VERSION ""

NS_ :

BS_:

BU_: XXX

BO_ 514 V_0x202: 8 XXX

BO_ 515 V_0x203: 8 XXX

BO_ 516 V_0x204: 8 XXX

BO_ 517 V_0x205: 8 XXX

BO_ 518 V_0x206: 8 XXX

BO_ 519 V_0x207: 8 XXX

BO_ 520 V_0x208: 8 XXX

BO_ 521 V_0x209: 8 XXX

BO_ 522 V_0x20a: 8 XXX

BO_ 523 V_0x20b: 8 XXX

BO_ 524 V_0x20c: 8 XXX

BO_ 568 V_0x238: 8 XXX

BO_ 569 V_0x239: 8 XXX

BO_ 570 V_0x23a: 8 XXX

BO_ 571 V_0x23b: 8 XXX

BO_ 572 V_0x23c: 8 XXX

BO_ 573 V_0x23d: 8 XXX

BO_ 574 V_0x23e: 8 XXX

BO_ 575 V_0x23f: 8 XXX

BO_ 576 V_0x240: 8 XXX

BO_ 577 V_0x241: 8 XXX

BO_ 578 V_0x242: 8 XXX

BO_ 579 V_0x243: 8 XXX

BO_ 580 V_0x244: 8 XXX

BO_ 581 V_0x245: 8 XXX

BO_ 582 V_0x246: 8 XXX

BO_ 583 V_0x247: 8 XXX

BO_ 584 V_0x248: 8 XXX

BO_ 585 V_0x249: 8 XXX

BO_ 586 V_0x24a: 8 XXX

BO_ 587 V_0x24b: 8 XXX

BO_ 588 V_0x24c: 8 XXX

BO_ 589 V_0x24d: 8 XXX

BO_ 590 V_0x24e: 8 XXX

BO_ 591 V_0x24f: 8 XXX

BO_ 592 V_0x250: 8 XXX

BO_ 593 V_0x251: 8 XXX

BO_ 594 V_0x252: 8 XXX

BO_ 595 V_0x253: 8 XXX

BO_ 596 V_0x254: 8 XXX

BO_ 597 V_0x255: 8 XXX

BO_ 602 V_0x25a: 8 XXX

BO_ 603 V_0x25b: 8 XXX

BO_ 604 V_0x25c: 8 XXX

BO_ 605 V_0x25d: 8 XXX

BO_ 606 V_0x25e: 8 XXX

BO_ 614 V_0x266: 8 XXX

BO_ 615 V_0x267: 8 XXX

BO_ 616 V_0x268: 8 XXX

BO_ 617 V_0x269: 8 XXX

BO_ 618 V_0x26a: 8 XXX

BO_ 619 V_0x26b: 8 XXX

BO_ 620 V_0x26c: 8 XXX

BO_ 621 V_0x26d: 8 XXX

BO_ 513 R_0x201: 8 XXX

BO_ 768 R_0x300: 8 XXX

BO_ 1024 R_0x400: 8 XXX

BO_ 1025 R_0x401: 8 XXX

BO_ 1026 R_0x402: 8 XXX

BO_ 1027 R_0x403: 8 XXX

BO_ 1028 R_0x404: 8 XXX

BO_ 1029 R_0x405: 8 XXX

BO_ 1030 R_0x406: 8 XXX

BO_ 1031 R_0x407: 8 XXX

BO_ 1032 R_0x408: 8 XXX

BO_ 1033 R_0x409: 8 XXX

BO_ 1034 R_0x40a: 8 XXX

BO_ 1035 R_0x40b: 8 XXX

BO_ 1036 R_0x40c: 8 XXX

BO_ 1037 R_0x40d: 8 XXX

BO_ 1038 R_0x40e: 8 XXX

BO_ 1039 R_0x40f: 8 XXX

BO_ 1040 R_0x410: 8 XXX

BO_ 1041 R_0x411: 8 XXX

BO_ 1042 R_0x412: 8 XXX

BO_ 1043 R_0x413: 8 XXX

BO_ 1044 R_0x414: 8 XXX

BO_ 1045 R_0x415: 8 XXX

BO_ 1046 R_0x416: 8 XXX

BO_ 1047 R_0x417: 8 XXX

BO_ 1048 R_0x418: 8 XXX

BO_ 1049 R_0x419: 8 XXX

BO_ 1050 R_0x41a: 8 XXX

BO_ 1051 R_0x41b: 8 XXX

BO_ 1052 R_0x41c: 8 XXX

BO_ 1053 R_0x41d: 8 XXX

BO_ 1054 R_0x41e: 8 XXX

BO_ 1055 R_0x41f: 8 XXX

BO_ 1056 R_0x420: 8 XXX

BO_ 1057 R_0x421: 8 XXX

BO_ 1058 R_0x422: 8 XXX

BO_ 1059 R_0x423: 8 XXX

BO_ 1060 R_0x424: 8 XXX

BO_ 1061 R_0x425: 8 XXX

BO_ 1062 R_0x426: 8 XXX

BO_ 1063 R_0x427: 8 XXX

BO_ 1248 R_0x4E0: 8 XXX
BO_ 1249 R_0x4E1: 8 XXX
BO_ 1250 R_0x4E2: 8 XXX
BO_ 1251 R_0x4E3: 8 XXX
BO_ 1252 R_0x4E4: 8 XXX
BO_ 1253 R_0x4E5: 8 XXX
BO_ 1254 R_0x4E6: 8 XXX
BO_ 1255 R_0x4E7: 8 XXX

BO_ 1530 R_0x5FA: 8 XXX
BO_ 1531 R_0x5FB: 8 XXX

BO_ 1533 R_0x5FD: 8 XXX
BO_ 1534 R_0x5FE: 8 XXX
BO_ 1535 R_0x5FF: 8 XXX

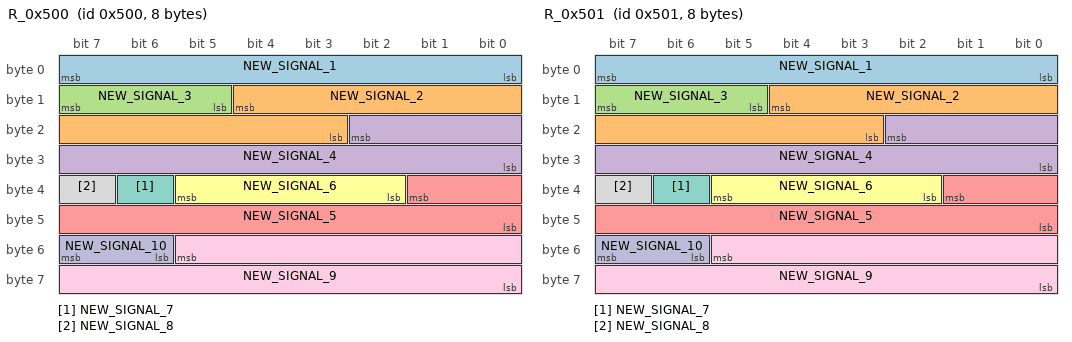
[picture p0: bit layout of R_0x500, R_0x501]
BO_ 1280 R_0x500: 8 XXX
 SG_ NEW_SIGNAL_1 : 7|8@0- (1,0) [-128|127] "" XXX
 SG_ NEW_SIGNAL_2 : 12|10@0- (0.2,0) [-102.4|102.2] "" XXX
 SG_ NEW_SIGNAL_3 : 15|3@0+ (1,0) [0|7] "" XXX
 SG_ NEW_SIGNAL_4 : 18|11@0+ (0.1,0) [0|204.7] "" XXX
 SG_ NEW_SIGNAL_5 : 33|10@0- (0.2,0) [-102.4|102.2] "" XXX
 SG_ NEW_SIGNAL_6 : 37|4@0+ (1,0) [0|255] "" XXX
 SG_ NEW_SIGNAL_7 : 38|1@0+ (1,0) [0|1] "" XXX
 SG_ NEW_SIGNAL_8 : 39|1@0+ (1,0) [0|1] "" XXX
 SG_ NEW_SIGNAL_9 : 53|14@0- (0.04,0) [-327.68|327.64] "" XXX
 SG_ NEW_SIGNAL_10 : 55|2@0+ (1,0) [0|3] "" XXX

BO_ 1281 R_0x501: 8 XXX
 SG_ NEW_SIGNAL_1 : 7|8@0- (1,0) [-128|127] "" XXX
 SG_ NEW_SIGNAL_2 : 12|10@0- (0.2,0) [-102.4|102.2] "" XXX
 SG_ NEW_SIGNAL_3 : 15|3@0+ (1,0) [0|7] "" XXX
 SG_ NEW_SIGNAL_4 : 18|11@0+ (0.1,0) [0|204.7] "" XXX
 SG_ NEW_SIGNAL_5 : 33|10@0- (0.2,0) [-102.4|102.2] "" XXX
 SG_ NEW_SIGNAL_6 : 37|4@0+ (1,0) [0|255] "" XXX
 SG_ NEW_SIGNAL_7 : 38|1@0+ (1,0) [0|1] "" XXX
 SG_ NEW_SIGNAL_8 : 39|1@0+ (1,0) [0|1] "" XXX
 SG_ NEW_SIGNAL_9 : 53|14@0- (0.04,0) [-327.68|327.64] "" XXX
 SG_ NEW_SIGNAL_10 : 55|2@0+ (1,0) [0|3] "" XXX

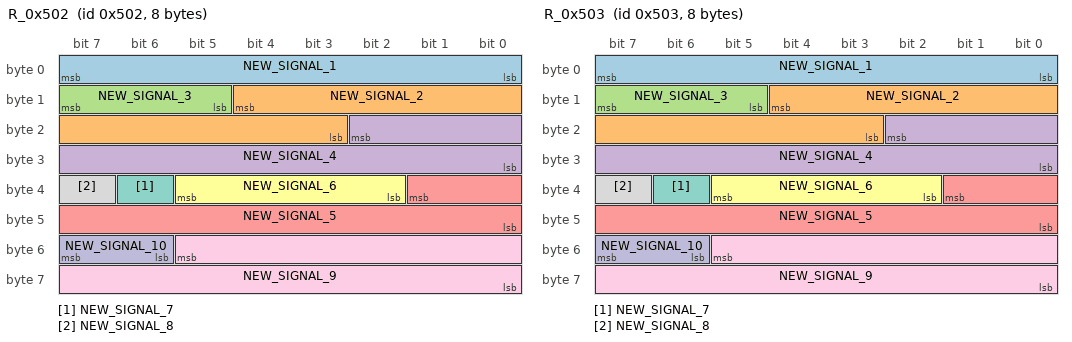
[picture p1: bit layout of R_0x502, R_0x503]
BO_ 1282 R_0x502: 8 XXX
 SG_ NEW_SIGNAL_1 : 7|8@0- (1,0) [-128|127] "" XXX
 SG_ NEW_SIGNAL_2 : 12|10@0- (0.2,0) [-102.4|102.2] "" XXX
 SG_ NEW_SIGNAL_3 : 15|3@0+ (1,0) [0|7] "" XXX
 SG_ NEW_SIGNAL_4 : 18|11@0+ (0.1,0) [0|204.7] "" XXX
 SG_ NEW_SIGNAL_5 : 33|10@0- (0.2,0) [-102.4|102.2] "" XXX
 SG_ NEW_SIGNAL_6 : 37|4@0+ (1,0) [0|255] "" XXX
 SG_ NEW_SIGNAL_7 : 38|1@0+ (1,0) [0|1] "" XXX
 SG_ NEW_SIGNAL_8 : 39|1@0+ (1,0) [0|1] "" XXX
 SG_ NEW_SIGNAL_9 : 53|14@0- (0.04,0) [-327.68|327.64] "" XXX
 SG_ NEW_SIGNAL_10 : 55|2@0+ (1,0) [0|3] "" XXX

BO_ 1283 R_0x503: 8 XXX
 SG_ NEW_SIGNAL_1 : 7|8@0- (1,0) [-128|127] "" XXX
 SG_ NEW_SIGNAL_2 : 12|10@0- (0.2,0) [-102.4|102.2] "" XXX
 SG_ NEW_SIGNAL_3 : 15|3@0+ (1,0) [0|7] "" XXX
 SG_ NEW_SIGNAL_4 : 18|11@0+ (0.1,0) [0|204.7] "" XXX
 SG_ NEW_SIGNAL_5 : 33|10@0- (0.2,0) [-102.4|102.2] "" XXX
 SG_ NEW_SIGNAL_6 : 37|4@0+ (1,0) [0|255] "" XXX
 SG_ NEW_SIGNAL_7 : 38|1@0+ (1,0) [0|1] "" XXX
 SG_ NEW_SIGNAL_8 : 39|1@0+ (1,0) [0|1] "" XXX
 SG_ NEW_SIGNAL_9 : 53|14@0- (0.04,0) [-327.68|327.64] "" XXX
 SG_ NEW_SIGNAL_10 : 55|2@0+ (1,0) [0|3] "" XXX

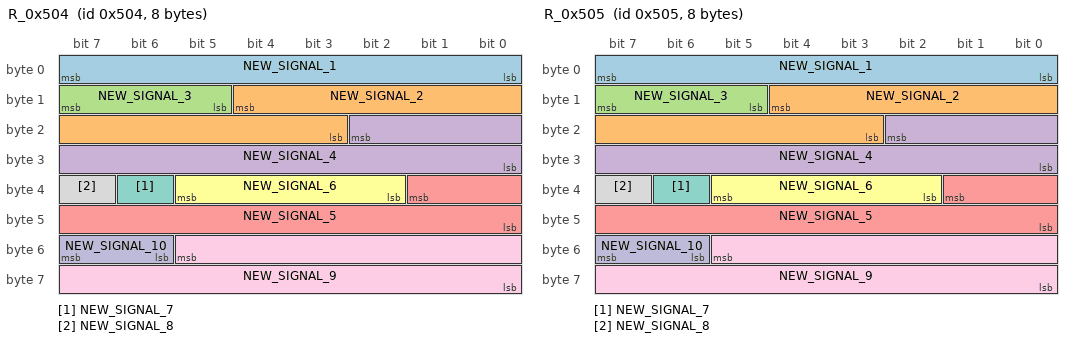
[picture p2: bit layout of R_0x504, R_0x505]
BO_ 1284 R_0x504: 8 XXX
 SG_ NEW_SIGNAL_1 : 7|8@0- (1,0) [-128|127] "" XXX
 SG_ NEW_SIGNAL_2 : 12|10@0- (0.2,0) [-102.4|102.2] "" XXX
 SG_ NEW_SIGNAL_3 : 15|3@0+ (1,0) [0|7] "" XXX
 SG_ NEW_SIGNAL_4 : 18|11@0+ (0.1,0) [0|204.7] "" XXX
 SG_ NEW_SIGNAL_5 : 33|10@0- (0.2,0) [-102.4|102.2] "" XXX
 SG_ NEW_SIGNAL_6 : 37|4@0+ (1,0) [0|255] "" XXX
 SG_ NEW_SIGNAL_7 : 38|1@0+ (1,0) [0|1] "" XXX
 SG_ NEW_SIGNAL_8 : 39|1@0+ (1,0) [0|1] "" XXX
 SG_ NEW_SIGNAL_9 : 53|14@0- (0.04,0) [-327.68|327.64] "" XXX
 SG_ NEW_SIGNAL_10 : 55|2@0+ (1,0) [0|3] "" XXX

BO_ 1285 R_0x505: 8 XXX
 SG_ NEW_SIGNAL_1 : 7|8@0- (1,0) [-128|127] "" XXX
 SG_ NEW_SIGNAL_2 : 12|10@0- (0.2,0) [-102.4|102.2] "" XXX
 SG_ NEW_SIGNAL_3 : 15|3@0+ (1,0) [0|7] "" XXX
 SG_ NEW_SIGNAL_4 : 18|11@0+ (0.1,0) [0|204.7] "" XXX
 SG_ NEW_SIGNAL_5 : 33|10@0- (0.2,0) [-102.4|102.2] "" XXX
 SG_ NEW_SIGNAL_6 : 37|4@0+ (1,0) [0|255] "" XXX
 SG_ NEW_SIGNAL_7 : 38|1@0+ (1,0) [0|1] "" XXX
 SG_ NEW_SIGNAL_8 : 39|1@0+ (1,0) [0|1] "" XXX
 SG_ NEW_SIGNAL_9 : 53|14@0- (0.04,0) [-327.68|327.64] "" XXX
 SG_ NEW_SIGNAL_10 : 55|2@0+ (1,0) [0|3] "" XXX

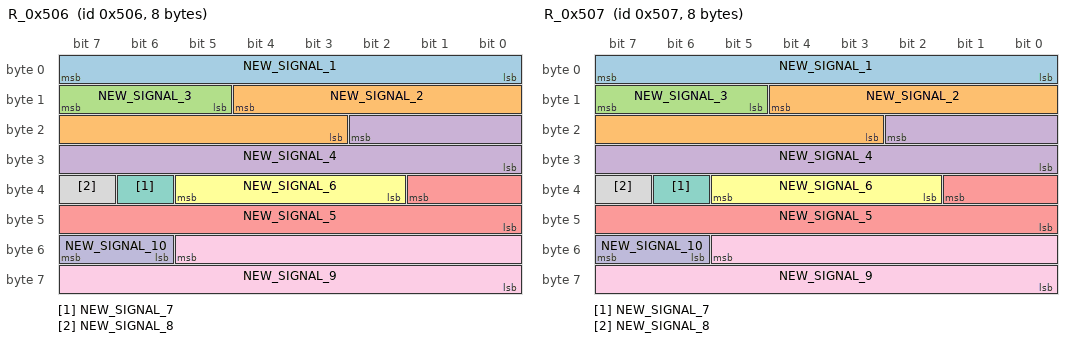
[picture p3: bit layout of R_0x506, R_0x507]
BO_ 1286 R_0x506: 8 XXX
 SG_ NEW_SIGNAL_1 : 7|8@0- (1,0) [-128|127] "" XXX
 SG_ NEW_SIGNAL_2 : 12|10@0- (0.2,0) [-102.4|102.2] "" XXX
 SG_ NEW_SIGNAL_3 : 15|3@0+ (1,0) [0|7] "" XXX
 SG_ NEW_SIGNAL_4 : 18|11@0+ (0.1,0) [0|204.7] "" XXX
 SG_ NEW_SIGNAL_5 : 33|10@0- (0.2,0) [-102.4|102.2] "" XXX
 SG_ NEW_SIGNAL_6 : 37|4@0+ (1,0) [0|255] "" XXX
 SG_ NEW_SIGNAL_7 : 38|1@0+ (1,0) [0|1] "" XXX
 SG_ NEW_SIGNAL_8 : 39|1@0+ (1,0) [0|1] "" XXX
 SG_ NEW_SIGNAL_9 : 53|14@0- (0.04,0) [-327.68|327.64] "" XXX
 SG_ NEW_SIGNAL_10 : 55|2@0+ (1,0) [0|3] "" XXX

BO_ 1287 R_0x507: 8 XXX
 SG_ NEW_SIGNAL_1 : 7|8@0- (1,0) [-128|127] "" XXX
 SG_ NEW_SIGNAL_2 : 12|10@0- (0.2,0) [-102.4|102.2] "" XXX
 SG_ NEW_SIGNAL_3 : 15|3@0+ (1,0) [0|7] "" XXX
 SG_ NEW_SIGNAL_4 : 18|11@0+ (0.1,0) [0|204.7] "" XXX
 SG_ NEW_SIGNAL_5 : 33|10@0- (0.2,0) [-102.4|102.2] "" XXX
 SG_ NEW_SIGNAL_6 : 37|4@0+ (1,0) [0|255] "" XXX
 SG_ NEW_SIGNAL_7 : 38|1@0+ (1,0) [0|1] "" XXX
 SG_ NEW_SIGNAL_8 : 39|1@0+ (1,0) [0|1] "" XXX
 SG_ NEW_SIGNAL_9 : 53|14@0- (0.04,0) [-327.68|327.64] "" XXX
 SG_ NEW_SIGNAL_10 : 55|2@0+ (1,0) [0|3] "" XXX

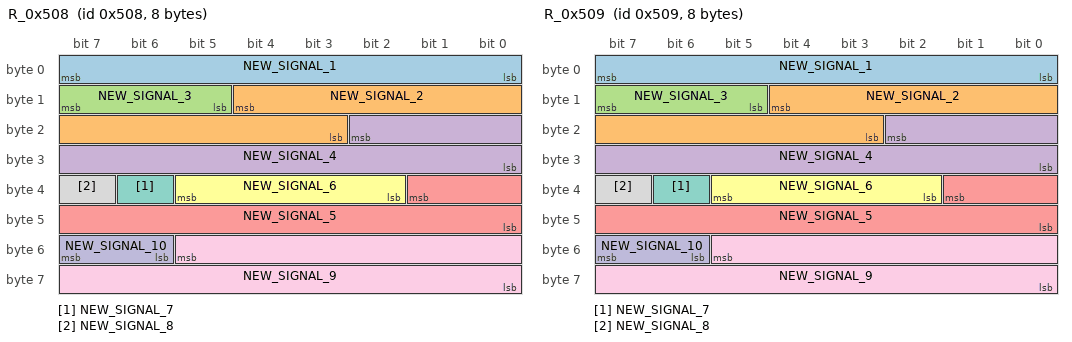
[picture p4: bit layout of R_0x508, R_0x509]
BO_ 1288 R_0x508: 8 XXX
 SG_ NEW_SIGNAL_1 : 7|8@0- (1,0) [-128|127] "" XXX
 SG_ NEW_SIGNAL_2 : 12|10@0- (0.2,0) [-102.4|102.2] "" XXX
 SG_ NEW_SIGNAL_3 : 15|3@0+ (1,0) [0|7] "" XXX
 SG_ NEW_SIGNAL_4 : 18|11@0+ (0.1,0) [0|204.7] "" XXX
 SG_ NEW_SIGNAL_5 : 33|10@0- (0.2,0) [-102.4|102.2] "" XXX
 SG_ NEW_SIGNAL_6 : 37|4@0+ (1,0) [0|255] "" XXX
 SG_ NEW_SIGNAL_7 : 38|1@0+ (1,0) [0|1] "" XXX
 SG_ NEW_SIGNAL_8 : 39|1@0+ (1,0) [0|1] "" XXX
 SG_ NEW_SIGNAL_9 : 53|14@0- (0.04,0) [-327.68|327.64] "" XXX
 SG_ NEW_SIGNAL_10 : 55|2@0+ (1,0) [0|3] "" XXX

BO_ 1289 R_0x509: 8 XXX
 SG_ NEW_SIGNAL_1 : 7|8@0- (1,0) [-128|127] "" XXX
 SG_ NEW_SIGNAL_2 : 12|10@0- (0.2,0) [-102.4|102.2] "" XXX
 SG_ NEW_SIGNAL_3 : 15|3@0+ (1,0) [0|7] "" XXX
 SG_ NEW_SIGNAL_4 : 18|11@0+ (0.1,0) [0|204.7] "" XXX
 SG_ NEW_SIGNAL_5 : 33|10@0- (0.2,0) [-102.4|102.2] "" XXX
 SG_ NEW_SIGNAL_6 : 37|4@0+ (1,0) [0|255] "" XXX
 SG_ NEW_SIGNAL_7 : 38|1@0+ (1,0) [0|1] "" XXX
 SG_ NEW_SIGNAL_8 : 39|1@0+ (1,0) [0|1] "" XXX
 SG_ NEW_SIGNAL_9 : 53|14@0- (0.04,0) [-327.68|327.64] "" XXX
 SG_ NEW_SIGNAL_10 : 55|2@0+ (1,0) [0|3] "" XXX

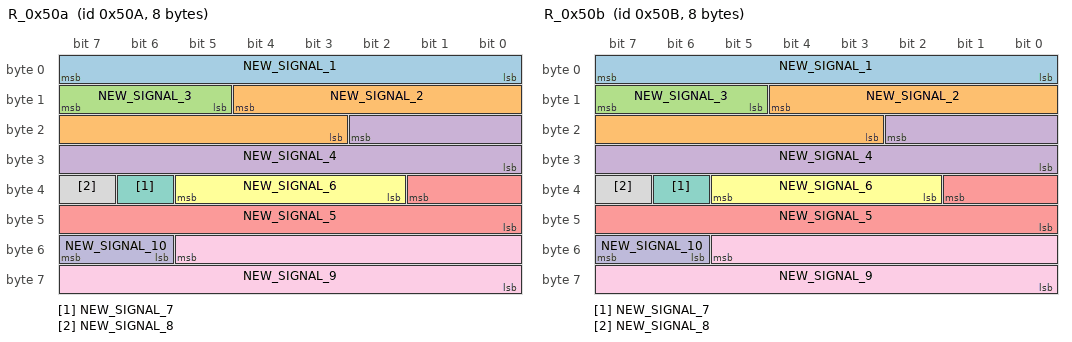
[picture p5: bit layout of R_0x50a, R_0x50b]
BO_ 1290 R_0x50a: 8 XXX
 SG_ NEW_SIGNAL_1 : 7|8@0- (1,0) [-128|127] "" XXX
 SG_ NEW_SIGNAL_2 : 12|10@0- (0.2,0) [-102.4|102.2] "" XXX
 SG_ NEW_SIGNAL_3 : 15|3@0+ (1,0) [0|7] "" XXX
 SG_ NEW_SIGNAL_4 : 18|11@0+ (0.1,0) [0|204.7] "" XXX
 SG_ NEW_SIGNAL_5 : 33|10@0- (0.2,0) [-102.4|102.2] "" XXX
 SG_ NEW_SIGNAL_6 : 37|4@0+ (1,0) [0|255] "" XXX
 SG_ NEW_SIGNAL_7 : 38|1@0+ (1,0) [0|1] "" XXX
 SG_ NEW_SIGNAL_8 : 39|1@0+ (1,0) [0|1] "" XXX
 SG_ NEW_SIGNAL_9 : 53|14@0- (0.04,0) [-327.68|327.64] "" XXX
 SG_ NEW_SIGNAL_10 : 55|2@0+ (1,0) [0|3] "" XXX

BO_ 1291 R_0x50b: 8 XXX
 SG_ NEW_SIGNAL_1 : 7|8@0- (1,0) [-128|127] "" XXX
 SG_ NEW_SIGNAL_2 : 12|10@0- (0.2,0) [-102.4|102.2] "" XXX
 SG_ NEW_SIGNAL_3 : 15|3@0+ (1,0) [0|7] "" XXX
 SG_ NEW_SIGNAL_4 : 18|11@0+ (0.1,0) [0|204.7] "" XXX
 SG_ NEW_SIGNAL_5 : 33|10@0- (0.2,0) [-102.4|102.2] "" XXX
 SG_ NEW_SIGNAL_6 : 37|4@0+ (1,0) [0|255] "" XXX
 SG_ NEW_SIGNAL_7 : 38|1@0+ (1,0) [0|1] "" XXX
 SG_ NEW_SIGNAL_8 : 39|1@0+ (1,0) [0|1] "" XXX
 SG_ NEW_SIGNAL_9 : 53|14@0- (0.04,0) [-327.68|327.64] "" XXX
 SG_ NEW_SIGNAL_10 : 55|2@0+ (1,0) [0|3] "" XXX

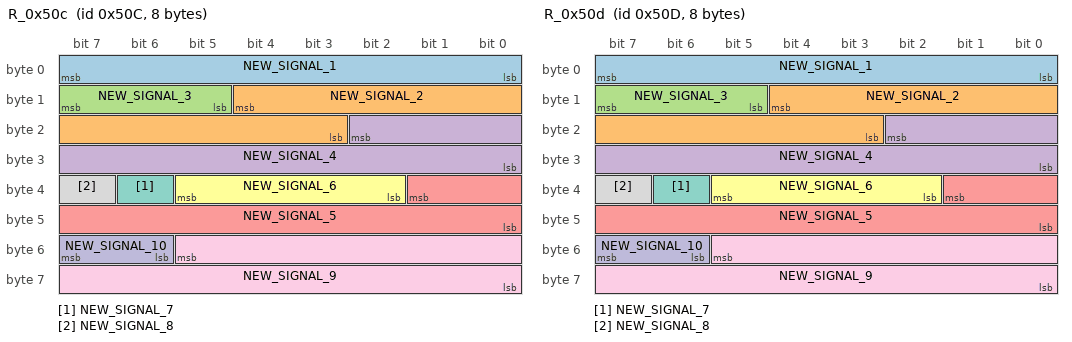
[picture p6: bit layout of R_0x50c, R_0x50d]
BO_ 1292 R_0x50c: 8 XXX
 SG_ NEW_SIGNAL_1 : 7|8@0- (1,0) [-128|127] "" XXX
 SG_ NEW_SIGNAL_2 : 12|10@0- (0.2,0) [-102.4|102.2] "" XXX
 SG_ NEW_SIGNAL_3 : 15|3@0+ (1,0) [0|7] "" XXX
 SG_ NEW_SIGNAL_4 : 18|11@0+ (0.1,0) [0|204.7] "" XXX
 SG_ NEW_SIGNAL_5 : 33|10@0- (0.2,0) [-102.4|102.2] "" XXX
 SG_ NEW_SIGNAL_6 : 37|4@0+ (1,0) [0|255] "" XXX
 SG_ NEW_SIGNAL_7 : 38|1@0+ (1,0) [0|1] "" XXX
 SG_ NEW_SIGNAL_8 : 39|1@0+ (1,0) [0|1] "" XXX
 SG_ NEW_SIGNAL_9 : 53|14@0- (0.04,0) [-327.68|327.64] "" XXX
 SG_ NEW_SIGNAL_10 : 55|2@0+ (1,0) [0|3] "" XXX

BO_ 1293 R_0x50d: 8 XXX
 SG_ NEW_SIGNAL_1 : 7|8@0- (1,0) [-128|127] "" XXX
 SG_ NEW_SIGNAL_2 : 12|10@0- (0.2,0) [-102.4|102.2] "" XXX
 SG_ NEW_SIGNAL_3 : 15|3@0+ (1,0) [0|7] "" XXX
 SG_ NEW_SIGNAL_4 : 18|11@0+ (0.1,0) [0|204.7] "" XXX
 SG_ NEW_SIGNAL_5 : 33|10@0- (0.2,0) [-102.4|102.2] "" XXX
 SG_ NEW_SIGNAL_6 : 37|4@0+ (1,0) [0|255] "" XXX
 SG_ NEW_SIGNAL_7 : 38|1@0+ (1,0) [0|1] "" XXX
 SG_ NEW_SIGNAL_8 : 39|1@0+ (1,0) [0|1] "" XXX
 SG_ NEW_SIGNAL_9 : 53|14@0- (0.04,0) [-327.68|327.64] "" XXX
 SG_ NEW_SIGNAL_10 : 55|2@0+ (1,0) [0|3] "" XXX

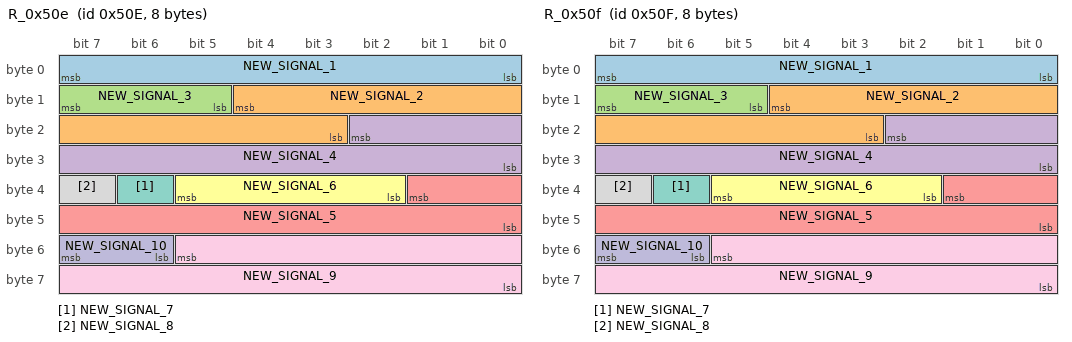
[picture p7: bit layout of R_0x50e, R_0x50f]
BO_ 1294 R_0x50e: 8 XXX
 SG_ NEW_SIGNAL_1 : 7|8@0- (1,0) [-128|127] "" XXX
 SG_ NEW_SIGNAL_2 : 12|10@0- (0.2,0) [-102.4|102.2] "" XXX
 SG_ NEW_SIGNAL_3 : 15|3@0+ (1,0) [0|7] "" XXX
 SG_ NEW_SIGNAL_4 : 18|11@0+ (0.1,0) [0|204.7] "" XXX
 SG_ NEW_SIGNAL_5 : 33|10@0- (0.2,0) [-102.4|102.2] "" XXX
 SG_ NEW_SIGNAL_6 : 37|4@0+ (1,0) [0|255] "" XXX
 SG_ NEW_SIGNAL_7 : 38|1@0+ (1,0) [0|1] "" XXX
 SG_ NEW_SIGNAL_8 : 39|1@0+ (1,0) [0|1] "" XXX
 SG_ NEW_SIGNAL_9 : 53|14@0- (0.04,0) [-327.68|327.64] "" XXX
 SG_ NEW_SIGNAL_10 : 55|2@0+ (1,0) [0|3] "" XXX

BO_ 1295 R_0x50f: 8 XXX
 SG_ NEW_SIGNAL_1 : 7|8@0- (1,0) [-128|127] "" XXX
 SG_ NEW_SIGNAL_2 : 12|10@0- (0.2,0) [-102.4|102.2] "" XXX
 SG_ NEW_SIGNAL_3 : 15|3@0+ (1,0) [0|7] "" XXX
 SG_ NEW_SIGNAL_4 : 18|11@0+ (0.1,0) [0|204.7] "" XXX
 SG_ NEW_SIGNAL_5 : 33|10@0- (0.2,0) [-102.4|102.2] "" XXX
 SG_ NEW_SIGNAL_6 : 37|4@0+ (1,0) [0|255] "" XXX
 SG_ NEW_SIGNAL_7 : 38|1@0+ (1,0) [0|1] "" XXX
 SG_ NEW_SIGNAL_8 : 39|1@0+ (1,0) [0|1] "" XXX
 SG_ NEW_SIGNAL_9 : 53|14@0- (0.04,0) [-327.68|327.64] "" XXX
 SG_ NEW_SIGNAL_10 : 55|2@0+ (1,0) [0|3] "" XXX

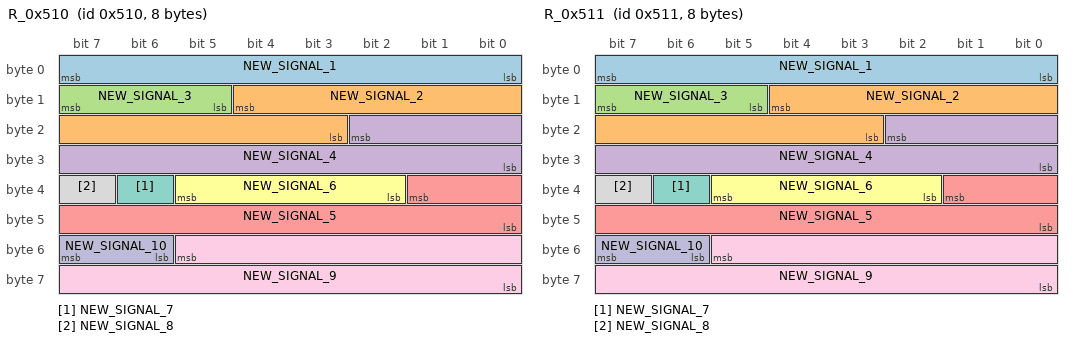
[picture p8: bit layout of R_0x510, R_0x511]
BO_ 1296 R_0x510: 8 XXX
 SG_ NEW_SIGNAL_1 : 7|8@0- (1,0) [-128|127] "" XXX
 SG_ NEW_SIGNAL_2 : 12|10@0- (0.2,0) [-102.4|102.2] "" XXX
 SG_ NEW_SIGNAL_3 : 15|3@0+ (1,0) [0|7] "" XXX
 SG_ NEW_SIGNAL_4 : 18|11@0+ (0.1,0) [0|204.7] "" XXX
 SG_ NEW_SIGNAL_5 : 33|10@0- (0.2,0) [-102.4|102.2] "" XXX
 SG_ NEW_SIGNAL_6 : 37|4@0+ (1,0) [0|255] "" XXX
 SG_ NEW_SIGNAL_7 : 38|1@0+ (1,0) [0|1] "" XXX
 SG_ NEW_SIGNAL_8 : 39|1@0+ (1,0) [0|1] "" XXX
 SG_ NEW_SIGNAL_9 : 53|14@0- (0.04,0) [-327.68|327.64] "" XXX
 SG_ NEW_SIGNAL_10 : 55|2@0+ (1,0) [0|3] "" XXX

BO_ 1297 R_0x511: 8 XXX
 SG_ NEW_SIGNAL_1 : 7|8@0- (1,0) [-128|127] "" XXX
 SG_ NEW_SIGNAL_2 : 12|10@0- (0.2,0) [-102.4|102.2] "" XXX
 SG_ NEW_SIGNAL_3 : 15|3@0+ (1,0) [0|7] "" XXX
 SG_ NEW_SIGNAL_4 : 18|11@0+ (0.1,0) [0|204.7] "" XXX
 SG_ NEW_SIGNAL_5 : 33|10@0- (0.2,0) [-102.4|102.2] "" XXX
 SG_ NEW_SIGNAL_6 : 37|4@0+ (1,0) [0|255] "" XXX
 SG_ NEW_SIGNAL_7 : 38|1@0+ (1,0) [0|1] "" XXX
 SG_ NEW_SIGNAL_8 : 39|1@0+ (1,0) [0|1] "" XXX
 SG_ NEW_SIGNAL_9 : 53|14@0- (0.04,0) [-327.68|327.64] "" XXX
 SG_ NEW_SIGNAL_10 : 55|2@0+ (1,0) [0|3] "" XXX

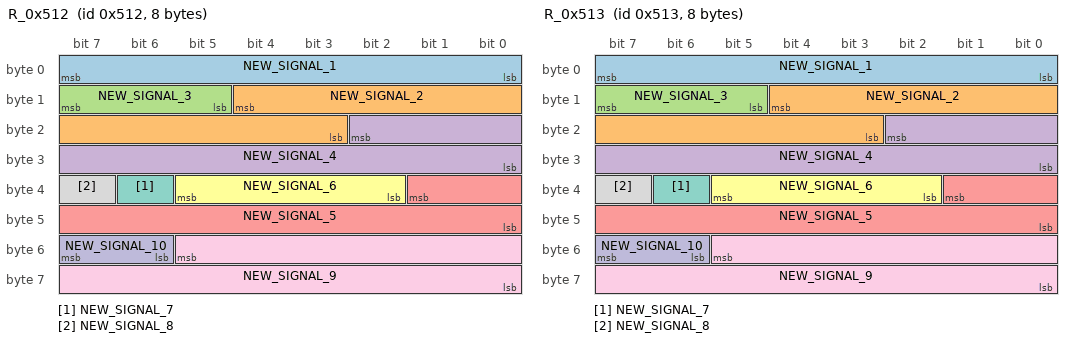
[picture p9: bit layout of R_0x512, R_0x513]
BO_ 1298 R_0x512: 8 XXX
 SG_ NEW_SIGNAL_1 : 7|8@0- (1,0) [-128|127] "" XXX
 SG_ NEW_SIGNAL_2 : 12|10@0- (0.2,0) [-102.4|102.2] "" XXX
 SG_ NEW_SIGNAL_3 : 15|3@0+ (1,0) [0|7] "" XXX
 SG_ NEW_SIGNAL_4 : 18|11@0+ (0.1,0) [0|204.7] "" XXX
 SG_ NEW_SIGNAL_5 : 33|10@0- (0.2,0) [-102.4|102.2] "" XXX
 SG_ NEW_SIGNAL_6 : 37|4@0+ (1,0) [0|255] "" XXX
 SG_ NEW_SIGNAL_7 : 38|1@0+ (1,0) [0|1] "" XXX
 SG_ NEW_SIGNAL_8 : 39|1@0+ (1,0) [0|1] "" XXX
 SG_ NEW_SIGNAL_9 : 53|14@0- (0.04,0) [-327.68|327.64] "" XXX
 SG_ NEW_SIGNAL_10 : 55|2@0+ (1,0) [0|3] "" XXX

BO_ 1299 R_0x513: 8 XXX
 SG_ NEW_SIGNAL_1 : 7|8@0- (1,0) [-128|127] "" XXX
 SG_ NEW_SIGNAL_2 : 12|10@0- (0.2,0) [-102.4|102.2] "" XXX
 SG_ NEW_SIGNAL_3 : 15|3@0+ (1,0) [0|7] "" XXX
 SG_ NEW_SIGNAL_4 : 18|11@0+ (0.1,0) [0|204.7] "" XXX
 SG_ NEW_SIGNAL_5 : 33|10@0- (0.2,0) [-102.4|102.2] "" XXX
 SG_ NEW_SIGNAL_6 : 37|4@0+ (1,0) [0|255] "" XXX
 SG_ NEW_SIGNAL_7 : 38|1@0+ (1,0) [0|1] "" XXX
 SG_ NEW_SIGNAL_8 : 39|1@0+ (1,0) [0|1] "" XXX
 SG_ NEW_SIGNAL_9 : 53|14@0- (0.04,0) [-327.68|327.64] "" XXX
 SG_ NEW_SIGNAL_10 : 55|2@0+ (1,0) [0|3] "" XXX

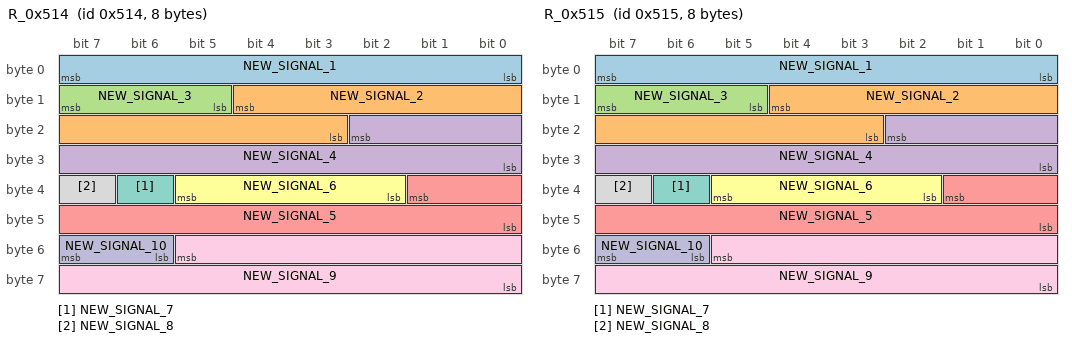
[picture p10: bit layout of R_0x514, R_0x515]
BO_ 1300 R_0x514: 8 XXX
 SG_ NEW_SIGNAL_1 : 7|8@0- (1,0) [-128|127] "" XXX
 SG_ NEW_SIGNAL_2 : 12|10@0- (0.2,0) [-102.4|102.2] "" XXX
 SG_ NEW_SIGNAL_3 : 15|3@0+ (1,0) [0|7] "" XXX
 SG_ NEW_SIGNAL_4 : 18|11@0+ (0.1,0) [0|204.7] "" XXX
 SG_ NEW_SIGNAL_5 : 33|10@0- (0.2,0) [-102.4|102.2] "" XXX
 SG_ NEW_SIGNAL_6 : 37|4@0+ (1,0) [0|255] "" XXX
 SG_ NEW_SIGNAL_7 : 38|1@0+ (1,0) [0|1] "" XXX
 SG_ NEW_SIGNAL_8 : 39|1@0+ (1,0) [0|1] "" XXX
 SG_ NEW_SIGNAL_9 : 53|14@0- (0.04,0) [-327.68|327.64] "" XXX
 SG_ NEW_SIGNAL_10 : 55|2@0+ (1,0) [0|3] "" XXX

BO_ 1301 R_0x515: 8 XXX
 SG_ NEW_SIGNAL_1 : 7|8@0- (1,0) [-128|127] "" XXX
 SG_ NEW_SIGNAL_2 : 12|10@0- (0.2,0) [-102.4|102.2] "" XXX
 SG_ NEW_SIGNAL_3 : 15|3@0+ (1,0) [0|7] "" XXX
 SG_ NEW_SIGNAL_4 : 18|11@0+ (0.1,0) [0|204.7] "" XXX
 SG_ NEW_SIGNAL_5 : 33|10@0- (0.2,0) [-102.4|102.2] "" XXX
 SG_ NEW_SIGNAL_6 : 37|4@0+ (1,0) [0|255] "" XXX
 SG_ NEW_SIGNAL_7 : 38|1@0+ (1,0) [0|1] "" XXX
 SG_ NEW_SIGNAL_8 : 39|1@0+ (1,0) [0|1] "" XXX
 SG_ NEW_SIGNAL_9 : 53|14@0- (0.04,0) [-327.68|327.64] "" XXX
 SG_ NEW_SIGNAL_10 : 55|2@0+ (1,0) [0|3] "" XXX

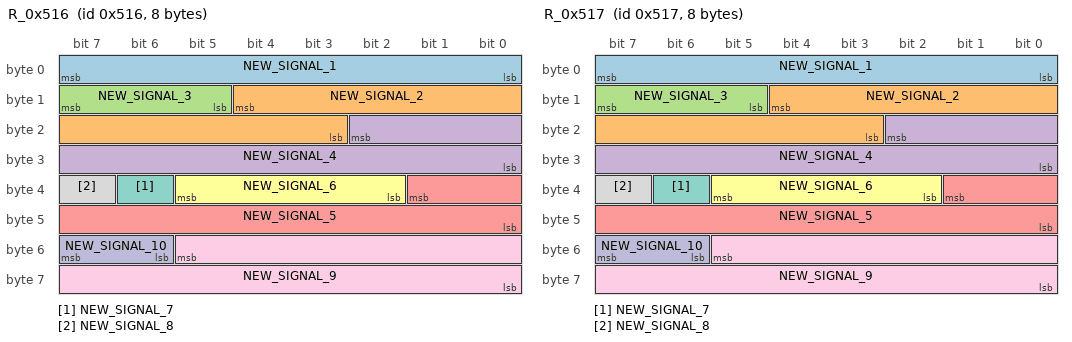
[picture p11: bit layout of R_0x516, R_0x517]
BO_ 1302 R_0x516: 8 XXX
 SG_ NEW_SIGNAL_1 : 7|8@0- (1,0) [-128|127] "" XXX
 SG_ NEW_SIGNAL_2 : 12|10@0- (0.2,0) [-102.4|102.2] "" XXX
 SG_ NEW_SIGNAL_3 : 15|3@0+ (1,0) [0|7] "" XXX
 SG_ NEW_SIGNAL_4 : 18|11@0+ (0.1,0) [0|204.7] "" XXX
 SG_ NEW_SIGNAL_5 : 33|10@0- (0.2,0) [-102.4|102.2] "" XXX
 SG_ NEW_SIGNAL_6 : 37|4@0+ (1,0) [0|255] "" XXX
 SG_ NEW_SIGNAL_7 : 38|1@0+ (1,0) [0|1] "" XXX
 SG_ NEW_SIGNAL_8 : 39|1@0+ (1,0) [0|1] "" XXX
 SG_ NEW_SIGNAL_9 : 53|14@0- (0.04,0) [-327.68|327.64] "" XXX
 SG_ NEW_SIGNAL_10 : 55|2@0+ (1,0) [0|3] "" XXX

BO_ 1303 R_0x517: 8 XXX
 SG_ NEW_SIGNAL_1 : 7|8@0- (1,0) [-128|127] "" XXX
 SG_ NEW_SIGNAL_2 : 12|10@0- (0.2,0) [-102.4|102.2] "" XXX
 SG_ NEW_SIGNAL_3 : 15|3@0+ (1,0) [0|7] "" XXX
 SG_ NEW_SIGNAL_4 : 18|11@0+ (0.1,0) [0|204.7] "" XXX
 SG_ NEW_SIGNAL_5 : 33|10@0- (0.2,0) [-102.4|102.2] "" XXX
 SG_ NEW_SIGNAL_6 : 37|4@0+ (1,0) [0|255] "" XXX
 SG_ NEW_SIGNAL_7 : 38|1@0+ (1,0) [0|1] "" XXX
 SG_ NEW_SIGNAL_8 : 39|1@0+ (1,0) [0|1] "" XXX
 SG_ NEW_SIGNAL_9 : 53|14@0- (0.04,0) [-327.68|327.64] "" XXX
 SG_ NEW_SIGNAL_10 : 55|2@0+ (1,0) [0|3] "" XXX

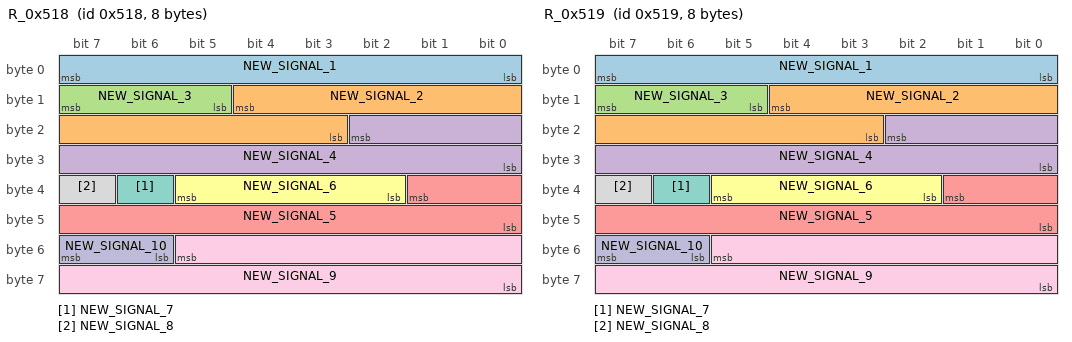
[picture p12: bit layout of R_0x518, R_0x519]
BO_ 1304 R_0x518: 8 XXX
 SG_ NEW_SIGNAL_1 : 7|8@0- (1,0) [-128|127] "" XXX
 SG_ NEW_SIGNAL_2 : 12|10@0- (0.2,0) [-102.4|102.2] "" XXX
 SG_ NEW_SIGNAL_3 : 15|3@0+ (1,0) [0|7] "" XXX
 SG_ NEW_SIGNAL_4 : 18|11@0+ (0.1,0) [0|204.7] "" XXX
 SG_ NEW_SIGNAL_5 : 33|10@0- (0.2,0) [-102.4|102.2] "" XXX
 SG_ NEW_SIGNAL_6 : 37|4@0+ (1,0) [0|255] "" XXX
 SG_ NEW_SIGNAL_7 : 38|1@0+ (1,0) [0|1] "" XXX
 SG_ NEW_SIGNAL_8 : 39|1@0+ (1,0) [0|1] "" XXX
 SG_ NEW_SIGNAL_9 : 53|14@0- (0.04,0) [-327.68|327.64] "" XXX
 SG_ NEW_SIGNAL_10 : 55|2@0+ (1,0) [0|3] "" XXX

BO_ 1305 R_0x519: 8 XXX
 SG_ NEW_SIGNAL_1 : 7|8@0- (1,0) [-128|127] "" XXX
 SG_ NEW_SIGNAL_2 : 12|10@0- (0.2,0) [-102.4|102.2] "" XXX
 SG_ NEW_SIGNAL_3 : 15|3@0+ (1,0) [0|7] "" XXX
 SG_ NEW_SIGNAL_4 : 18|11@0+ (0.1,0) [0|204.7] "" XXX
 SG_ NEW_SIGNAL_5 : 33|10@0- (0.2,0) [-102.4|102.2] "" XXX
 SG_ NEW_SIGNAL_6 : 37|4@0+ (1,0) [0|255] "" XXX
 SG_ NEW_SIGNAL_7 : 38|1@0+ (1,0) [0|1] "" XXX
 SG_ NEW_SIGNAL_8 : 39|1@0+ (1,0) [0|1] "" XXX
 SG_ NEW_SIGNAL_9 : 53|14@0- (0.04,0) [-327.68|327.64] "" XXX
 SG_ NEW_SIGNAL_10 : 55|2@0+ (1,0) [0|3] "" XXX

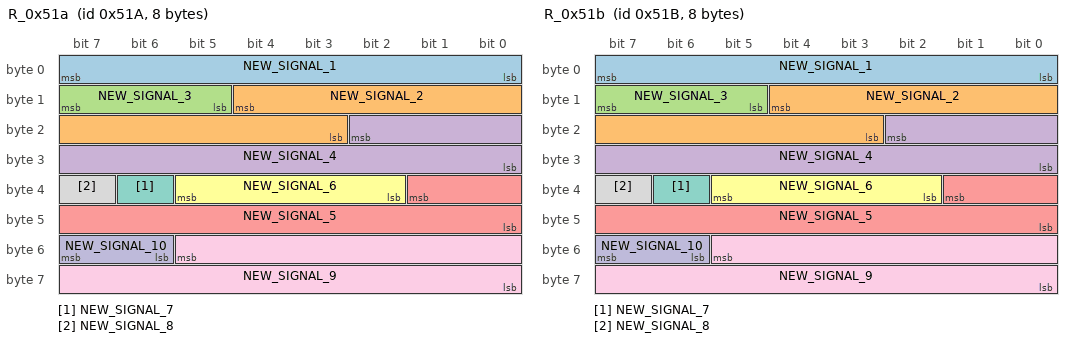
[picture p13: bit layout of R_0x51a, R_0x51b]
BO_ 1306 R_0x51a: 8 XXX
 SG_ NEW_SIGNAL_1 : 7|8@0- (1,0) [-128|127] "" XXX
 SG_ NEW_SIGNAL_2 : 12|10@0- (0.2,0) [-102.4|102.2] "" XXX
 SG_ NEW_SIGNAL_3 : 15|3@0+ (1,0) [0|7] "" XXX
 SG_ NEW_SIGNAL_4 : 18|11@0+ (0.1,0) [0|204.7] "" XXX
 SG_ NEW_SIGNAL_5 : 33|10@0- (0.2,0) [-102.4|102.2] "" XXX
 SG_ NEW_SIGNAL_6 : 37|4@0+ (1,0) [0|255] "" XXX
 SG_ NEW_SIGNAL_7 : 38|1@0+ (1,0) [0|1] "" XXX
 SG_ NEW_SIGNAL_8 : 39|1@0+ (1,0) [0|1] "" XXX
 SG_ NEW_SIGNAL_9 : 53|14@0- (0.04,0) [-327.68|327.64] "" XXX
 SG_ NEW_SIGNAL_10 : 55|2@0+ (1,0) [0|3] "" XXX

BO_ 1307 R_0x51b: 8 XXX
 SG_ NEW_SIGNAL_1 : 7|8@0- (1,0) [-128|127] "" XXX
 SG_ NEW_SIGNAL_2 : 12|10@0- (0.2,0) [-102.4|102.2] "" XXX
 SG_ NEW_SIGNAL_3 : 15|3@0+ (1,0) [0|7] "" XXX
 SG_ NEW_SIGNAL_4 : 18|11@0+ (0.1,0) [0|204.7] "" XXX
 SG_ NEW_SIGNAL_5 : 33|10@0- (0.2,0) [-102.4|102.2] "" XXX
 SG_ NEW_SIGNAL_6 : 37|4@0+ (1,0) [0|255] "" XXX
 SG_ NEW_SIGNAL_7 : 38|1@0+ (1,0) [0|1] "" XXX
 SG_ NEW_SIGNAL_8 : 39|1@0+ (1,0) [0|1] "" XXX
 SG_ NEW_SIGNAL_9 : 53|14@0- (0.04,0) [-327.68|327.64] "" XXX
 SG_ NEW_SIGNAL_10 : 55|2@0+ (1,0) [0|3] "" XXX

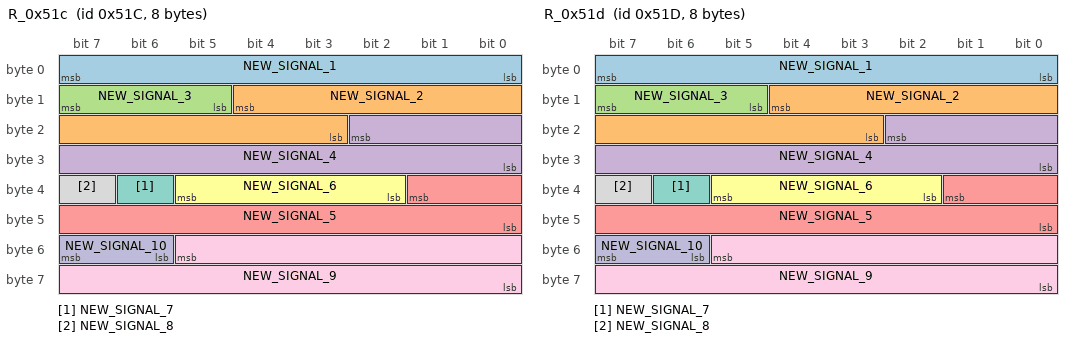
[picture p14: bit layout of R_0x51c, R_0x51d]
BO_ 1308 R_0x51c: 8 XXX
 SG_ NEW_SIGNAL_1 : 7|8@0- (1,0) [-128|127] "" XXX
 SG_ NEW_SIGNAL_2 : 12|10@0- (0.2,0) [-102.4|102.2] "" XXX
 SG_ NEW_SIGNAL_3 : 15|3@0+ (1,0) [0|7] "" XXX
 SG_ NEW_SIGNAL_4 : 18|11@0+ (0.1,0) [0|204.7] "" XXX
 SG_ NEW_SIGNAL_5 : 33|10@0- (0.2,0) [-102.4|102.2] "" XXX
 SG_ NEW_SIGNAL_6 : 37|4@0+ (1,0) [0|255] "" XXX
 SG_ NEW_SIGNAL_7 : 38|1@0+ (1,0) [0|1] "" XXX
 SG_ NEW_SIGNAL_8 : 39|1@0+ (1,0) [0|1] "" XXX
 SG_ NEW_SIGNAL_9 : 53|14@0- (0.04,0) [-327.68|327.64] "" XXX
 SG_ NEW_SIGNAL_10 : 55|2@0+ (1,0) [0|3] "" XXX

BO_ 1309 R_0x51d: 8 XXX
 SG_ NEW_SIGNAL_1 : 7|8@0- (1,0) [-128|127] "" XXX
 SG_ NEW_SIGNAL_2 : 12|10@0- (0.2,0) [-102.4|102.2] "" XXX
 SG_ NEW_SIGNAL_3 : 15|3@0+ (1,0) [0|7] "" XXX
 SG_ NEW_SIGNAL_4 : 18|11@0+ (0.1,0) [0|204.7] "" XXX
 SG_ NEW_SIGNAL_5 : 33|10@0- (0.2,0) [-102.4|102.2] "" XXX
 SG_ NEW_SIGNAL_6 : 37|4@0+ (1,0) [0|255] "" XXX
 SG_ NEW_SIGNAL_7 : 38|1@0+ (1,0) [0|1] "" XXX
 SG_ NEW_SIGNAL_8 : 39|1@0+ (1,0) [0|1] "" XXX
 SG_ NEW_SIGNAL_9 : 53|14@0- (0.04,0) [-327.68|327.64] "" XXX
 SG_ NEW_SIGNAL_10 : 55|2@0+ (1,0) [0|3] "" XXX

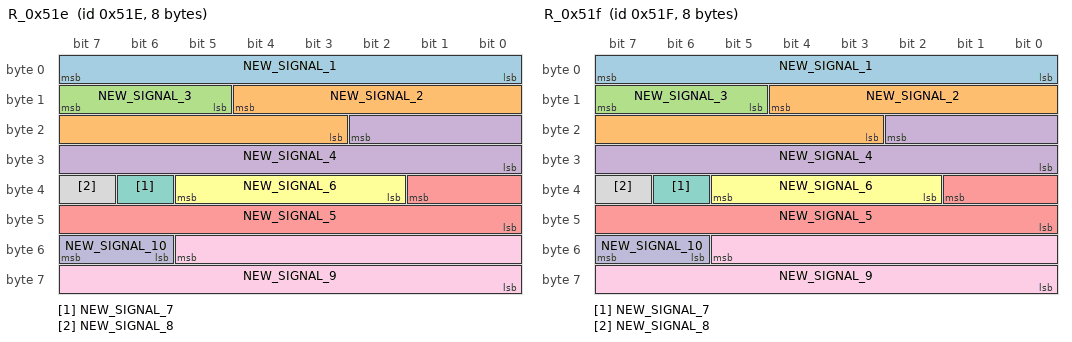
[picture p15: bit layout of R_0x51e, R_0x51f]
BO_ 1310 R_0x51e: 8 XXX
 SG_ NEW_SIGNAL_1 : 7|8@0- (1,0) [-128|127] "" XXX
 SG_ NEW_SIGNAL_2 : 12|10@0- (0.2,0) [-102.4|102.2] "" XXX
 SG_ NEW_SIGNAL_3 : 15|3@0+ (1,0) [0|7] "" XXX
 SG_ NEW_SIGNAL_4 : 18|11@0+ (0.1,0) [0|204.7] "" XXX
 SG_ NEW_SIGNAL_5 : 33|10@0- (0.2,0) [-102.4|102.2] "" XXX
 SG_ NEW_SIGNAL_6 : 37|4@0+ (1,0) [0|255] "" XXX
 SG_ NEW_SIGNAL_7 : 38|1@0+ (1,0) [0|1] "" XXX
 SG_ NEW_SIGNAL_8 : 39|1@0+ (1,0) [0|1] "" XXX
 SG_ NEW_SIGNAL_9 : 53|14@0- (0.04,0) [-327.68|327.64] "" XXX
 SG_ NEW_SIGNAL_10 : 55|2@0+ (1,0) [0|3] "" XXX

BO_ 1311 R_0x51f: 8 XXX
 SG_ NEW_SIGNAL_1 : 7|8@0- (1,0) [-128|127] "" XXX
 SG_ NEW_SIGNAL_2 : 12|10@0- (0.2,0) [-102.4|102.2] "" XXX
 SG_ NEW_SIGNAL_3 : 15|3@0+ (1,0) [0|7] "" XXX
 SG_ NEW_SIGNAL_4 : 18|11@0+ (0.1,0) [0|204.7] "" XXX
 SG_ NEW_SIGNAL_5 : 33|10@0- (0.2,0) [-102.4|102.2] "" XXX
 SG_ NEW_SIGNAL_6 : 37|4@0+ (1,0) [0|255] "" XXX
 SG_ NEW_SIGNAL_7 : 38|1@0+ (1,0) [0|1] "" XXX
 SG_ NEW_SIGNAL_8 : 39|1@0+ (1,0) [0|1] "" XXX
 SG_ NEW_SIGNAL_9 : 53|14@0- (0.04,0) [-327.68|327.64] "" XXX
 SG_ NEW_SIGNAL_10 : 55|2@0+ (1,0) [0|3] "" XXX

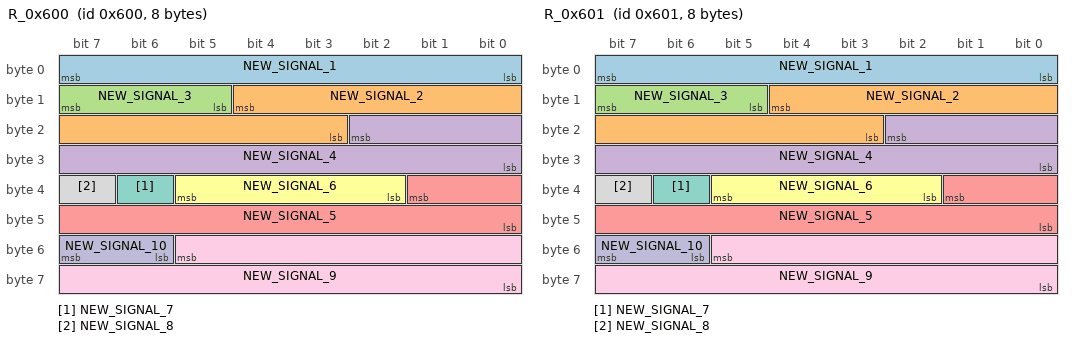
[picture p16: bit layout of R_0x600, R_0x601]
BO_ 1536 R_0x600: 8 XXX
 SG_ NEW_SIGNAL_1 : 7|8@0- (1,0) [-128|127] "" XXX
 SG_ NEW_SIGNAL_2 : 12|10@0- (0.2,0) [-102.4|102.2] "" XXX
 SG_ NEW_SIGNAL_3 : 15|3@0+ (1,0) [0|7] "" XXX
 SG_ NEW_SIGNAL_4 : 18|11@0+ (0.1,0) [0|204.7] "" XXX
 SG_ NEW_SIGNAL_5 : 33|10@0- (0.2,0) [-102.4|102.2] "" XXX
 SG_ NEW_SIGNAL_6 : 37|4@0+ (1,0) [0|255] "" XXX
 SG_ NEW_SIGNAL_7 : 38|1@0+ (1,0) [0|1] "" XXX
 SG_ NEW_SIGNAL_8 : 39|1@0+ (1,0) [0|1] "" XXX
 SG_ NEW_SIGNAL_9 : 53|14@0- (0.04,0) [-327.68|327.64] "" XXX
 SG_ NEW_SIGNAL_10 : 55|2@0+ (1,0) [0|3] "" XXX

BO_ 1537 R_0x601: 8 XXX
 SG_ NEW_SIGNAL_1 : 7|8@0- (1,0) [-128|127] "" XXX
 SG_ NEW_SIGNAL_2 : 12|10@0- (0.2,0) [-102.4|102.2] "" XXX
 SG_ NEW_SIGNAL_3 : 15|3@0+ (1,0) [0|7] "" XXX
 SG_ NEW_SIGNAL_4 : 18|11@0+ (0.1,0) [0|204.7] "" XXX
 SG_ NEW_SIGNAL_5 : 33|10@0- (0.2,0) [-102.4|102.2] "" XXX
 SG_ NEW_SIGNAL_6 : 37|4@0+ (1,0) [0|255] "" XXX
 SG_ NEW_SIGNAL_7 : 38|1@0+ (1,0) [0|1] "" XXX
 SG_ NEW_SIGNAL_8 : 39|1@0+ (1,0) [0|1] "" XXX
 SG_ NEW_SIGNAL_9 : 53|14@0- (0.04,0) [-327.68|327.64] "" XXX
 SG_ NEW_SIGNAL_10 : 55|2@0+ (1,0) [0|3] "" XXX

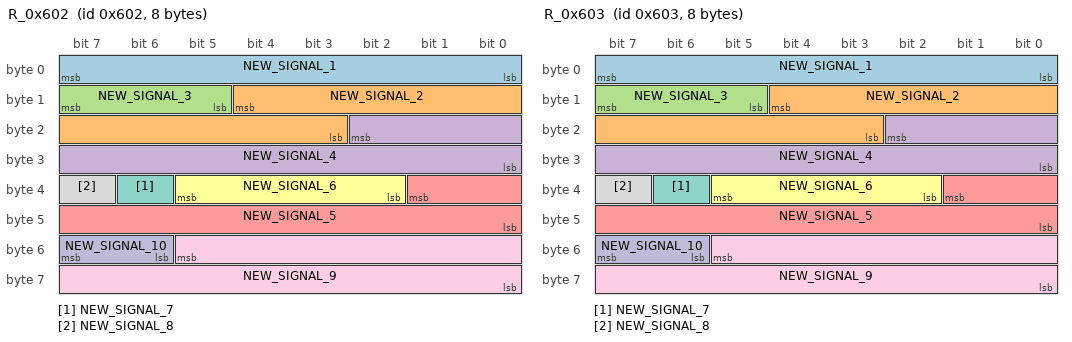
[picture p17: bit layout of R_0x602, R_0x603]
BO_ 1538 R_0x602: 8 XXX
 SG_ NEW_SIGNAL_1 : 7|8@0- (1,0) [-128|127] "" XXX
 SG_ NEW_SIGNAL_2 : 12|10@0- (0.2,0) [-102.4|102.2] "" XXX
 SG_ NEW_SIGNAL_3 : 15|3@0+ (1,0) [0|7] "" XXX
 SG_ NEW_SIGNAL_4 : 18|11@0+ (0.1,0) [0|204.7] "" XXX
 SG_ NEW_SIGNAL_5 : 33|10@0- (0.2,0) [-102.4|102.2] "" XXX
 SG_ NEW_SIGNAL_6 : 37|4@0+ (1,0) [0|255] "" XXX
 SG_ NEW_SIGNAL_7 : 38|1@0+ (1,0) [0|1] "" XXX
 SG_ NEW_SIGNAL_8 : 39|1@0+ (1,0) [0|1] "" XXX
 SG_ NEW_SIGNAL_9 : 53|14@0- (0.04,0) [-327.68|327.64] "" XXX
 SG_ NEW_SIGNAL_10 : 55|2@0+ (1,0) [0|3] "" XXX

BO_ 1539 R_0x603: 8 XXX
 SG_ NEW_SIGNAL_1 : 7|8@0- (1,0) [-128|127] "" XXX
 SG_ NEW_SIGNAL_2 : 12|10@0- (0.2,0) [-102.4|102.2] "" XXX
 SG_ NEW_SIGNAL_3 : 15|3@0+ (1,0) [0|7] "" XXX
 SG_ NEW_SIGNAL_4 : 18|11@0+ (0.1,0) [0|204.7] "" XXX
 SG_ NEW_SIGNAL_5 : 33|10@0- (0.2,0) [-102.4|102.2] "" XXX
 SG_ NEW_SIGNAL_6 : 37|4@0+ (1,0) [0|255] "" XXX
 SG_ NEW_SIGNAL_7 : 38|1@0+ (1,0) [0|1] "" XXX
 SG_ NEW_SIGNAL_8 : 39|1@0+ (1,0) [0|1] "" XXX
 SG_ NEW_SIGNAL_9 : 53|14@0- (0.04,0) [-327.68|327.64] "" XXX
 SG_ NEW_SIGNAL_10 : 55|2@0+ (1,0) [0|3] "" XXX

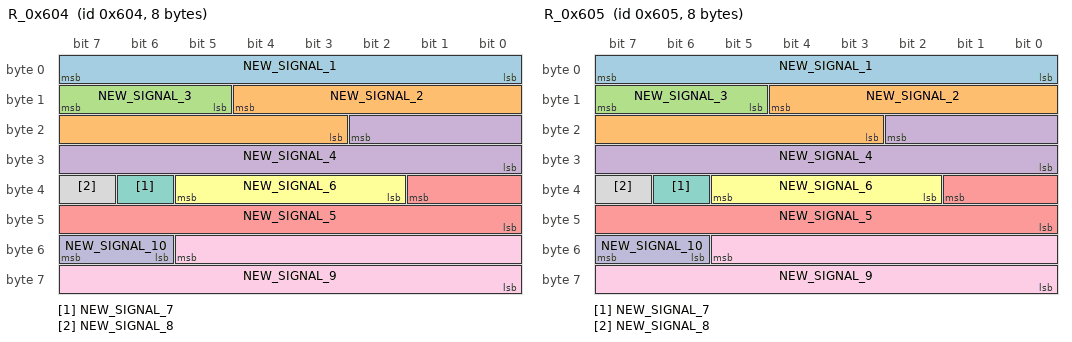
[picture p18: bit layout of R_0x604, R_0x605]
BO_ 1540 R_0x604: 8 XXX
 SG_ NEW_SIGNAL_1 : 7|8@0- (1,0) [-128|127] "" XXX
 SG_ NEW_SIGNAL_2 : 12|10@0- (0.2,0) [-102.4|102.2] "" XXX
 SG_ NEW_SIGNAL_3 : 15|3@0+ (1,0) [0|7] "" XXX
 SG_ NEW_SIGNAL_4 : 18|11@0+ (0.1,0) [0|204.7] "" XXX
 SG_ NEW_SIGNAL_5 : 33|10@0- (0.2,0) [-102.4|102.2] "" XXX
 SG_ NEW_SIGNAL_6 : 37|4@0+ (1,0) [0|255] "" XXX
 SG_ NEW_SIGNAL_7 : 38|1@0+ (1,0) [0|1] "" XXX
 SG_ NEW_SIGNAL_8 : 39|1@0+ (1,0) [0|1] "" XXX
 SG_ NEW_SIGNAL_9 : 53|14@0- (0.04,0) [-327.68|327.64] "" XXX
 SG_ NEW_SIGNAL_10 : 55|2@0+ (1,0) [0|3] "" XXX

BO_ 1541 R_0x605: 8 XXX
 SG_ NEW_SIGNAL_1 : 7|8@0- (1,0) [-128|127] "" XXX
 SG_ NEW_SIGNAL_2 : 12|10@0- (0.2,0) [-102.4|102.2] "" XXX
 SG_ NEW_SIGNAL_3 : 15|3@0+ (1,0) [0|7] "" XXX
 SG_ NEW_SIGNAL_4 : 18|11@0+ (0.1,0) [0|204.7] "" XXX
 SG_ NEW_SIGNAL_5 : 33|10@0- (0.2,0) [-102.4|102.2] "" XXX
 SG_ NEW_SIGNAL_6 : 37|4@0+ (1,0) [0|255] "" XXX
 SG_ NEW_SIGNAL_7 : 38|1@0+ (1,0) [0|1] "" XXX
 SG_ NEW_SIGNAL_8 : 39|1@0+ (1,0) [0|1] "" XXX
 SG_ NEW_SIGNAL_9 : 53|14@0- (0.04,0) [-327.68|327.64] "" XXX
 SG_ NEW_SIGNAL_10 : 55|2@0+ (1,0) [0|3] "" XXX

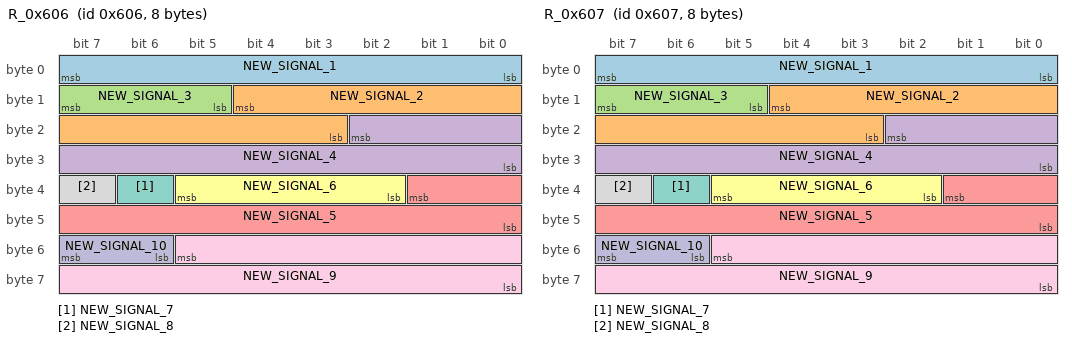
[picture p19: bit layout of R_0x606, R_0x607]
BO_ 1542 R_0x606: 8 XXX
 SG_ NEW_SIGNAL_1 : 7|8@0- (1,0) [-128|127] "" XXX
 SG_ NEW_SIGNAL_2 : 12|10@0- (0.2,0) [-102.4|102.2] "" XXX
 SG_ NEW_SIGNAL_3 : 15|3@0+ (1,0) [0|7] "" XXX
 SG_ NEW_SIGNAL_4 : 18|11@0+ (0.1,0) [0|204.7] "" XXX
 SG_ NEW_SIGNAL_5 : 33|10@0- (0.2,0) [-102.4|102.2] "" XXX
 SG_ NEW_SIGNAL_6 : 37|4@0+ (1,0) [0|255] "" XXX
 SG_ NEW_SIGNAL_7 : 38|1@0+ (1,0) [0|1] "" XXX
 SG_ NEW_SIGNAL_8 : 39|1@0+ (1,0) [0|1] "" XXX
 SG_ NEW_SIGNAL_9 : 53|14@0- (0.04,0) [-327.68|327.64] "" XXX
 SG_ NEW_SIGNAL_10 : 55|2@0+ (1,0) [0|3] "" XXX

BO_ 1543 R_0x607: 8 XXX
 SG_ NEW_SIGNAL_1 : 7|8@0- (1,0) [-128|127] "" XXX
 SG_ NEW_SIGNAL_2 : 12|10@0- (0.2,0) [-102.4|102.2] "" XXX
 SG_ NEW_SIGNAL_3 : 15|3@0+ (1,0) [0|7] "" XXX
 SG_ NEW_SIGNAL_4 : 18|11@0+ (0.1,0) [0|204.7] "" XXX
 SG_ NEW_SIGNAL_5 : 33|10@0- (0.2,0) [-102.4|102.2] "" XXX
 SG_ NEW_SIGNAL_6 : 37|4@0+ (1,0) [0|255] "" XXX
 SG_ NEW_SIGNAL_7 : 38|1@0+ (1,0) [0|1] "" XXX
 SG_ NEW_SIGNAL_8 : 39|1@0+ (1,0) [0|1] "" XXX
 SG_ NEW_SIGNAL_9 : 53|14@0- (0.04,0) [-327.68|327.64] "" XXX
 SG_ NEW_SIGNAL_10 : 55|2@0+ (1,0) [0|3] "" XXX

BO_ 1544 R_0x608: 8 XXX
 SG_ NEW_SIGNAL_1 : 7|8@0- (1,0) [-128|127] "" XXX
 SG_ NEW_SIGNAL_2 : 12|10@0- (0.2,0) [-102.4|102.2] "" XXX
 SG_ NEW_SIGNAL_3 : 15|3@0+ (1,0) [0|7] "" XXX
 SG_ NEW_SIGNAL_4 : 18|11@0+ (0.1,0) [0|204.7] "" XXX
 SG_ NEW_SIGNAL_5 : 33|10@0- (0.2,0) [-102.4|102.2] "" XXX
 SG_ NEW_SIGNAL_6 : 37|4@0+ (1,0) [0|255] "" XXX
 SG_ NEW_SIGNAL_7 : 38|1@0+ (1,0) [0|1] "" XXX
 SG_ NEW_SIGNAL_8 : 39|1@0+ (1,0) [0|1] "" XXX
 SG_ NEW_SIGNAL_9 : 53|14@0- (0.04,0) [-327.68|327.64] "" XXX
 SG_ NEW_SIGNAL_10 : 55|2@0+ (1,0) [0|3] "" XXX

BO_ 1545 R_0x609: 8 XXX
 SG_ NEW_SIGNAL_1 : 7|8@0- (1,0) [-128|127] "" XXX
 SG_ NEW_SIGNAL_2 : 12|10@0- (0.2,0) [-102.4|102.2] "" XXX
 SG_ NEW_SIGNAL_3 : 15|3@0+ (1,0) [0|7] "" XXX
 SG_ NEW_SIGNAL_4 : 18|11@0+ (0.1,0) [0|204.7] "" XXX
 SG_ NEW_SIGNAL_5 : 33|10@0- (0.2,0) [-102.4|102.2] "" XXX
 SG_ NEW_SIGNAL_6 : 37|4@0+ (1,0) [0|255] "" XXX
 SG_ NEW_SIGNAL_7 : 38|1@0+ (1,0) [0|1] "" XXX
 SG_ NEW_SIGNAL_8 : 39|1@0+ (1,0) [0|1] "" XXX
 SG_ NEW_SIGNAL_9 : 53|14@0- (0.04,0) [-327.68|327.64] "" XXX
 SG_ NEW_SIGNAL_10 : 55|2@0+ (1,0) [0|3] "" XXX

BO_ 1546 R_0x60a: 8 XXX
 SG_ NEW_SIGNAL_1 : 7|8@0- (1,0) [-128|127] "" XXX
 SG_ NEW_SIGNAL_2 : 12|10@0- (0.2,0) [-102.4|102.2] "" XXX
 SG_ NEW_SIGNAL_3 : 15|3@0+ (1,0) [0|7] "" XXX
 SG_ NEW_SIGNAL_4 : 18|11@0+ (0.1,0) [0|204.7] "" XXX
 SG_ NEW_SIGNAL_5 : 33|10@0- (0.2,0) [-102.4|102.2] "" XXX
 SG_ NEW_SIGNAL_6 : 37|4@0+ (1,0) [0|255] "" XXX
 SG_ NEW_SIGNAL_7 : 38|1@0+ (1,0) [0|1] "" XXX
 SG_ NEW_SIGNAL_8 : 39|1@0+ (1,0) [0|1] "" XXX
 SG_ NEW_SIGNAL_9 : 53|14@0- (0.04,0) [-327.68|327.64] "" XXX
 SG_ NEW_SIGNAL_10 : 55|2@0+ (1,0) [0|3] "" XXX

BO_ 1547 R_0x60b: 8 XXX
 SG_ NEW_SIGNAL_1 : 7|8@0- (1,0) [-128|127] "" XXX
 SG_ NEW_SIGNAL_2 : 12|10@0- (0.2,0) [-102.4|102.2] "" XXX
 SG_ NEW_SIGNAL_3 : 15|3@0+ (1,0) [0|7] "" XXX
 SG_ NEW_SIGNAL_4 : 18|11@0+ (0.1,0) [0|204.7] "" XXX
 SG_ NEW_SIGNAL_5 : 33|10@0- (0.2,0) [-102.4|102.2] "" XXX
 SG_ NEW_SIGNAL_6 : 37|4@0+ (1,0) [0|255] "" XXX
 SG_ NEW_SIGNAL_7 : 38|1@0+ (1,0) [0|1] "" XXX
 SG_ NEW_SIGNAL_8 : 39|1@0+ (1,0) [0|1] "" XXX
 SG_ NEW_SIGNAL_9 : 53|14@0- (0.04,0) [-327.68|327.64] "" XXX
 SG_ NEW_SIGNAL_10 : 55|2@0+ (1,0) [0|3] "" XXX

BO_ 1548 R_0x60c: 8 XXX
 SG_ NEW_SIGNAL_1 : 7|8@0- (1,0) [-128|127] "" XXX
 SG_ NEW_SIGNAL_2 : 12|10@0- (0.2,0) [-102.4|102.2] "" XXX
 SG_ NEW_SIGNAL_3 : 15|3@0+ (1,0) [0|7] "" XXX
 SG_ NEW_SIGNAL_4 : 18|11@0+ (0.1,0) [0|204.7] "" XXX
 SG_ NEW_SIGNAL_5 : 33|10@0- (0.2,0) [-102.4|102.2] "" XXX
 SG_ NEW_SIGNAL_6 : 37|4@0+ (1,0) [0|255] "" XXX
 SG_ NEW_SIGNAL_7 : 38|1@0+ (1,0) [0|1] "" XXX
 SG_ NEW_SIGNAL_8 : 39|1@0+ (1,0) [0|1] "" XXX
 SG_ NEW_SIGNAL_9 : 53|14@0- (0.04,0) [-327.68|327.64] "" XXX
 SG_ NEW_SIGNAL_10 : 55|2@0+ (1,0) [0|3] "" XXX

BO_ 1549 R_0x60d: 8 XXX
 SG_ NEW_SIGNAL_1 : 7|8@0- (1,0) [-128|127] "" XXX
 SG_ NEW_SIGNAL_2 : 12|10@0- (0.2,0) [-102.4|102.2] "" XXX
 SG_ NEW_SIGNAL_3 : 15|3@0+ (1,0) [0|7] "" XXX
 SG_ NEW_SIGNAL_4 : 18|11@0+ (0.1,0) [0|204.7] "" XXX
 SG_ NEW_SIGNAL_5 : 33|10@0- (0.2,0) [-102.4|102.2] "" XXX
 SG_ NEW_SIGNAL_6 : 37|4@0+ (1,0) [0|255] "" XXX
 SG_ NEW_SIGNAL_7 : 38|1@0+ (1,0) [0|1] "" XXX
 SG_ NEW_SIGNAL_8 : 39|1@0+ (1,0) [0|1] "" XXX
 SG_ NEW_SIGNAL_9 : 53|14@0- (0.04,0) [-327.68|327.64] "" XXX
 SG_ NEW_SIGNAL_10 : 55|2@0+ (1,0) [0|3] "" XXX

BO_ 1550 R_0x60e: 8 XXX
 SG_ NEW_SIGNAL_1 : 7|8@0- (1,0) [-128|127] "" XXX
 SG_ NEW_SIGNAL_2 : 12|10@0- (0.2,0) [-102.4|102.2] "" XXX
 SG_ NEW_SIGNAL_3 : 15|3@0+ (1,0) [0|7] "" XXX
 SG_ NEW_SIGNAL_4 : 18|11@0+ (0.1,0) [0|204.7] "" XXX
 SG_ NEW_SIGNAL_5 : 33|10@0- (0.2,0) [-102.4|102.2] "" XXX
 SG_ NEW_SIGNAL_6 : 37|4@0+ (1,0) [0|255] "" XXX
 SG_ NEW_SIGNAL_7 : 38|1@0+ (1,0) [0|1] "" XXX
 SG_ NEW_SIGNAL_8 : 39|1@0+ (1,0) [0|1] "" XXX
 SG_ NEW_SIGNAL_9 : 53|14@0- (0.04,0) [-327.68|327.64] "" XXX
 SG_ NEW_SIGNAL_10 : 55|2@0+ (1,0) [0|3] "" XXX

BO_ 1551 R_0x60f: 8 XXX
 SG_ NEW_SIGNAL_1 : 7|8@0- (1,0) [-128|127] "" XXX
 SG_ NEW_SIGNAL_2 : 12|10@0- (0.2,0) [-102.4|102.2] "" XXX
 SG_ NEW_SIGNAL_3 : 15|3@0+ (1,0) [0|7] "" XXX
 SG_ NEW_SIGNAL_4 : 18|11@0+ (0.1,0) [0|204.7] "" XXX
 SG_ NEW_SIGNAL_5 : 33|10@0- (0.2,0) [-102.4|102.2] "" XXX
 SG_ NEW_SIGNAL_6 : 37|4@0+ (1,0) [0|255] "" XXX
 SG_ NEW_SIGNAL_7 : 38|1@0+ (1,0) [0|1] "" XXX
 SG_ NEW_SIGNAL_8 : 39|1@0+ (1,0) [0|1] "" XXX
 SG_ NEW_SIGNAL_9 : 53|14@0- (0.04,0) [-327.68|327.64] "" XXX
 SG_ NEW_SIGNAL_10 : 55|2@0+ (1,0) [0|3] "" XXX

BO_ 1552 R_0x610: 8 XXX
 SG_ NEW_SIGNAL_1 : 7|8@0- (1,0) [-128|127] "" XXX
 SG_ NEW_SIGNAL_2 : 12|10@0- (0.2,0) [-102.4|102.2] "" XXX
 SG_ NEW_SIGNAL_3 : 15|3@0+ (1,0) [0|7] "" XXX
 SG_ NEW_SIGNAL_4 : 18|11@0+ (0.1,0) [0|204.7] "" XXX
 SG_ NEW_SIGNAL_5 : 33|10@0- (0.2,0) [-102.4|102.2] "" XXX
 SG_ NEW_SIGNAL_6 : 37|4@0+ (1,0) [0|255] "" XXX
 SG_ NEW_SIGNAL_7 : 38|1@0+ (1,0) [0|1] "" XXX
 SG_ NEW_SIGNAL_8 : 39|1@0+ (1,0) [0|1] "" XXX
 SG_ NEW_SIGNAL_9 : 53|14@0- (0.04,0) [-327.68|327.64] "" XXX
 SG_ NEW_SIGNAL_10 : 55|2@0+ (1,0) [0|3] "" XXX

BO_ 1553 R_0x611: 8 XXX
 SG_ NEW_SIGNAL_1 : 7|8@0- (1,0) [-128|127] "" XXX
 SG_ NEW_SIGNAL_2 : 12|10@0- (0.2,0) [-102.4|102.2] "" XXX
 SG_ NEW_SIGNAL_3 : 15|3@0+ (1,0) [0|7] "" XXX
 SG_ NEW_SIGNAL_4 : 18|11@0+ (0.1,0) [0|204.7] "" XXX
 SG_ NEW_SIGNAL_5 : 33|10@0- (0.2,0) [-102.4|102.2] "" XXX
 SG_ NEW_SIGNAL_6 : 37|4@0+ (1,0) [0|255] "" XXX
 SG_ NEW_SIGNAL_7 : 38|1@0+ (1,0) [0|1] "" XXX
 SG_ NEW_SIGNAL_8 : 39|1@0+ (1,0) [0|1] "" XXX
 SG_ NEW_SIGNAL_9 : 53|14@0- (0.04,0) [-327.68|327.64] "" XXX
 SG_ NEW_SIGNAL_10 : 55|2@0+ (1,0) [0|3] "" XXX

BO_ 1554 R_0x612: 8 XXX
 SG_ NEW_SIGNAL_1 : 7|8@0- (1,0) [-128|127] "" XXX
 SG_ NEW_SIGNAL_2 : 12|10@0- (0.2,0) [-102.4|102.2] "" XXX
 SG_ NEW_SIGNAL_3 : 15|3@0+ (1,0) [0|7] "" XXX
 SG_ NEW_SIGNAL_4 : 18|11@0+ (0.1,0) [0|204.7] "" XXX
 SG_ NEW_SIGNAL_5 : 33|10@0- (0.2,0) [-102.4|102.2] "" XXX
 SG_ NEW_SIGNAL_6 : 37|4@0+ (1,0) [0|255] "" XXX
 SG_ NEW_SIGNAL_7 : 38|1@0+ (1,0) [0|1] "" XXX
 SG_ NEW_SIGNAL_8 : 39|1@0+ (1,0) [0|1] "" XXX
 SG_ NEW_SIGNAL_9 : 53|14@0- (0.04,0) [-327.68|327.64] "" XXX
 SG_ NEW_SIGNAL_10 : 55|2@0+ (1,0) [0|3] "" XXX

BO_ 1555 R_0x613: 8 XXX
 SG_ NEW_SIGNAL_1 : 7|8@0- (1,0) [-128|127] "" XXX
 SG_ NEW_SIGNAL_2 : 12|10@0- (0.2,0) [-102.4|102.2] "" XXX
 SG_ NEW_SIGNAL_3 : 15|3@0+ (1,0) [0|7] "" XXX
 SG_ NEW_SIGNAL_4 : 18|11@0+ (0.1,0) [0|204.7] "" XXX
 SG_ NEW_SIGNAL_5 : 33|10@0- (0.2,0) [-102.4|102.2] "" XXX
 SG_ NEW_SIGNAL_6 : 37|4@0+ (1,0) [0|255] "" XXX
 SG_ NEW_SIGNAL_7 : 38|1@0+ (1,0) [0|1] "" XXX
 SG_ NEW_SIGNAL_8 : 39|1@0+ (1,0) [0|1] "" XXX
 SG_ NEW_SIGNAL_9 : 53|14@0- (0.04,0) [-327.68|327.64] "" XXX
 SG_ NEW_SIGNAL_10 : 55|2@0+ (1,0) [0|3] "" XXX

BO_ 1556 R_0x614: 8 XXX
 SG_ NEW_SIGNAL_1 : 7|8@0- (1,0) [-128|127] "" XXX
 SG_ NEW_SIGNAL_2 : 12|10@0- (0.2,0) [-102.4|102.2] "" XXX
 SG_ NEW_SIGNAL_3 : 15|3@0+ (1,0) [0|7] "" XXX
 SG_ NEW_SIGNAL_4 : 18|11@0+ (0.1,0) [0|204.7] "" XXX
 SG_ NEW_SIGNAL_5 : 33|10@0- (0.2,0) [-102.4|102.2] "" XXX
 SG_ NEW_SIGNAL_6 : 37|4@0+ (1,0) [0|255] "" XXX
 SG_ NEW_SIGNAL_7 : 38|1@0+ (1,0) [0|1] "" XXX
 SG_ NEW_SIGNAL_8 : 39|1@0+ (1,0) [0|1] "" XXX
 SG_ NEW_SIGNAL_9 : 53|14@0- (0.04,0) [-327.68|327.64] "" XXX
 SG_ NEW_SIGNAL_10 : 55|2@0+ (1,0) [0|3] "" XXX

BO_ 1557 R_0x615: 8 XXX
 SG_ NEW_SIGNAL_1 : 7|8@0- (1,0) [-128|127] "" XXX
 SG_ NEW_SIGNAL_2 : 12|10@0- (0.2,0) [-102.4|102.2] "" XXX
 SG_ NEW_SIGNAL_3 : 15|3@0+ (1,0) [0|7] "" XXX
 SG_ NEW_SIGNAL_4 : 18|11@0+ (0.1,0) [0|204.7] "" XXX
 SG_ NEW_SIGNAL_5 : 33|10@0- (0.2,0) [-102.4|102.2] "" XXX
 SG_ NEW_SIGNAL_6 : 37|4@0+ (1,0) [0|255] "" XXX
 SG_ NEW_SIGNAL_7 : 38|1@0+ (1,0) [0|1] "" XXX
 SG_ NEW_SIGNAL_8 : 39|1@0+ (1,0) [0|1] "" XXX
 SG_ NEW_SIGNAL_9 : 53|14@0- (0.04,0) [-327.68|327.64] "" XXX
 SG_ NEW_SIGNAL_10 : 55|2@0+ (1,0) [0|3] "" XXX

BO_ 1558 R_0x616: 8 XXX
 SG_ NEW_SIGNAL_1 : 7|8@0- (1,0) [-128|127] "" XXX
 SG_ NEW_SIGNAL_2 : 12|10@0- (0.2,0) [-102.4|102.2] "" XXX
 SG_ NEW_SIGNAL_3 : 15|3@0+ (1,0) [0|7] "" XXX
 SG_ NEW_SIGNAL_4 : 18|11@0+ (0.1,0) [0|204.7] "" XXX
 SG_ NEW_SIGNAL_5 : 33|10@0- (0.2,0) [-102.4|102.2] "" XXX
 SG_ NEW_SIGNAL_6 : 37|4@0+ (1,0) [0|255] "" XXX
 SG_ NEW_SIGNAL_7 : 38|1@0+ (1,0) [0|1] "" XXX
 SG_ NEW_SIGNAL_8 : 39|1@0+ (1,0) [0|1] "" XXX
 SG_ NEW_SIGNAL_9 : 53|14@0- (0.04,0) [-327.68|327.64] "" XXX
 SG_ NEW_SIGNAL_10 : 55|2@0+ (1,0) [0|3] "" XXX

BO_ 1559 R_0x617: 8 XXX
 SG_ NEW_SIGNAL_1 : 7|8@0- (1,0) [-128|127] "" XXX
 SG_ NEW_SIGNAL_2 : 12|10@0- (0.2,0) [-102.4|102.2] "" XXX
 SG_ NEW_SIGNAL_3 : 15|3@0+ (1,0) [0|7] "" XXX
 SG_ NEW_SIGNAL_4 : 18|11@0+ (0.1,0) [0|204.7] "" XXX
 SG_ NEW_SIGNAL_5 : 33|10@0- (0.2,0) [-102.4|102.2] "" XXX
 SG_ NEW_SIGNAL_6 : 37|4@0+ (1,0) [0|255] "" XXX
 SG_ NEW_SIGNAL_7 : 38|1@0+ (1,0) [0|1] "" XXX
 SG_ NEW_SIGNAL_8 : 39|1@0+ (1,0) [0|1] "" XXX
 SG_ NEW_SIGNAL_9 : 53|14@0- (0.04,0) [-327.68|327.64] "" XXX
 SG_ NEW_SIGNAL_10 : 55|2@0+ (1,0) [0|3] "" XXX

BO_ 1560 R_0x618: 8 XXX
 SG_ NEW_SIGNAL_1 : 7|8@0- (1,0) [-128|127] "" XXX
 SG_ NEW_SIGNAL_2 : 12|10@0- (0.2,0) [-102.4|102.2] "" XXX
 SG_ NEW_SIGNAL_3 : 15|3@0+ (1,0) [0|7] "" XXX
 SG_ NEW_SIGNAL_4 : 18|11@0+ (0.1,0) [0|204.7] "" XXX
 SG_ NEW_SIGNAL_5 : 33|10@0- (0.2,0) [-102.4|102.2] "" XXX
 SG_ NEW_SIGNAL_6 : 37|4@0+ (1,0) [0|255] "" XXX
 SG_ NEW_SIGNAL_7 : 38|1@0+ (1,0) [0|1] "" XXX
 SG_ NEW_SIGNAL_8 : 39|1@0+ (1,0) [0|1] "" XXX
 SG_ NEW_SIGNAL_9 : 53|14@0- (0.04,0) [-327.68|327.64] "" XXX
 SG_ NEW_SIGNAL_10 : 55|2@0+ (1,0) [0|3] "" XXX

BO_ 1561 R_0x619: 8 XXX
 SG_ NEW_SIGNAL_1 : 7|8@0- (1,0) [-128|127] "" XXX
 SG_ NEW_SIGNAL_2 : 12|10@0- (0.2,0) [-102.4|102.2] "" XXX
 SG_ NEW_SIGNAL_3 : 15|3@0+ (1,0) [0|7] "" XXX
 SG_ NEW_SIGNAL_4 : 18|11@0+ (0.1,0) [0|204.7] "" XXX
 SG_ NEW_SIGNAL_5 : 33|10@0- (0.2,0) [-102.4|102.2] "" XXX
 SG_ NEW_SIGNAL_6 : 37|4@0+ (1,0) [0|255] "" XXX
 SG_ NEW_SIGNAL_7 : 38|1@0+ (1,0) [0|1] "" XXX
 SG_ NEW_SIGNAL_8 : 39|1@0+ (1,0) [0|1] "" XXX
 SG_ NEW_SIGNAL_9 : 53|14@0- (0.04,0) [-327.68|327.64] "" XXX
 SG_ NEW_SIGNAL_10 : 55|2@0+ (1,0) [0|3] "" XXX

BO_ 1562 R_0x61a: 8 XXX
 SG_ NEW_SIGNAL_1 : 7|8@0- (1,0) [-128|127] "" XXX
 SG_ NEW_SIGNAL_2 : 12|10@0- (0.2,0) [-102.4|102.2] "" XXX
 SG_ NEW_SIGNAL_3 : 15|3@0+ (1,0) [0|7] "" XXX
 SG_ NEW_SIGNAL_4 : 18|11@0+ (0.1,0) [0|204.7] "" XXX
 SG_ NEW_SIGNAL_5 : 33|10@0- (0.2,0) [-102.4|102.2] "" XXX
 SG_ NEW_SIGNAL_6 : 37|4@0+ (1,0) [0|255] "" XXX
 SG_ NEW_SIGNAL_7 : 38|1@0+ (1,0) [0|1] "" XXX
 SG_ NEW_SIGNAL_8 : 39|1@0+ (1,0) [0|1] "" XXX
 SG_ NEW_SIGNAL_9 : 53|14@0- (0.04,0) [-327.68|327.64] "" XXX
 SG_ NEW_SIGNAL_10 : 55|2@0+ (1,0) [0|3] "" XXX

BO_ 1563 R_0x61b: 8 XXX
 SG_ NEW_SIGNAL_1 : 7|8@0- (1,0) [-128|127] "" XXX
 SG_ NEW_SIGNAL_2 : 12|10@0- (0.2,0) [-102.4|102.2] "" XXX
 SG_ NEW_SIGNAL_3 : 15|3@0+ (1,0) [0|7] "" XXX
 SG_ NEW_SIGNAL_4 : 18|11@0+ (0.1,0) [0|204.7] "" XXX
 SG_ NEW_SIGNAL_5 : 33|10@0- (0.2,0) [-102.4|102.2] "" XXX
 SG_ NEW_SIGNAL_6 : 37|4@0+ (1,0) [0|255] "" XXX
 SG_ NEW_SIGNAL_7 : 38|1@0+ (1,0) [0|1] "" XXX
 SG_ NEW_SIGNAL_8 : 39|1@0+ (1,0) [0|1] "" XXX
 SG_ NEW_SIGNAL_9 : 53|14@0- (0.04,0) [-327.68|327.64] "" XXX
 SG_ NEW_SIGNAL_10 : 55|2@0+ (1,0) [0|3] "" XXX

BO_ 1564 R_0x61c: 8 XXX
 SG_ NEW_SIGNAL_1 : 7|8@0- (1,0) [-128|127] "" XXX
 SG_ NEW_SIGNAL_2 : 12|10@0- (0.2,0) [-102.4|102.2] "" XXX
 SG_ NEW_SIGNAL_3 : 15|3@0+ (1,0) [0|7] "" XXX
 SG_ NEW_SIGNAL_4 : 18|11@0+ (0.1,0) [0|204.7] "" XXX
 SG_ NEW_SIGNAL_5 : 33|10@0- (0.2,0) [-102.4|102.2] "" XXX
 SG_ NEW_SIGNAL_6 : 37|4@0+ (1,0) [0|255] "" XXX
 SG_ NEW_SIGNAL_7 : 38|1@0+ (1,0) [0|1] "" XXX
 SG_ NEW_SIGNAL_8 : 39|1@0+ (1,0) [0|1] "" XXX
 SG_ NEW_SIGNAL_9 : 53|14@0- (0.04,0) [-327.68|327.64] "" XXX
 SG_ NEW_SIGNAL_10 : 55|2@0+ (1,0) [0|3] "" XXX

BO_ 1565 R_0x61d: 8 XXX
 SG_ NEW_SIGNAL_1 : 7|8@0- (1,0) [-128|127] "" XXX
 SG_ NEW_SIGNAL_2 : 12|10@0- (0.2,0) [-102.4|102.2] "" XXX
 SG_ NEW_SIGNAL_3 : 15|3@0+ (1,0) [0|7] "" XXX
 SG_ NEW_SIGNAL_4 : 18|11@0+ (0.1,0) [0|204.7] "" XXX
 SG_ NEW_SIGNAL_5 : 33|10@0- (0.2,0) [-102.4|102.2] "" XXX
 SG_ NEW_SIGNAL_6 : 37|4@0+ (1,0) [0|255] "" XXX
 SG_ NEW_SIGNAL_7 : 38|1@0+ (1,0) [0|1] "" XXX
 SG_ NEW_SIGNAL_8 : 39|1@0+ (1,0) [0|1] "" XXX
 SG_ NEW_SIGNAL_9 : 53|14@0- (0.04,0) [-327.68|327.64] "" XXX
 SG_ NEW_SIGNAL_10 : 55|2@0+ (1,0) [0|3] "" XXX

BO_ 1566 R_0x61e: 8 XXX
 SG_ NEW_SIGNAL_1 : 7|8@0- (1,0) [-128|127] "" XXX
 SG_ NEW_SIGNAL_2 : 12|10@0- (0.2,0) [-102.4|102.2] "" XXX
 SG_ NEW_SIGNAL_3 : 15|3@0+ (1,0) [0|7] "" XXX
 SG_ NEW_SIGNAL_4 : 18|11@0+ (0.1,0) [0|204.7] "" XXX
 SG_ NEW_SIGNAL_5 : 33|10@0- (0.2,0) [-102.4|102.2] "" XXX
 SG_ NEW_SIGNAL_6 : 37|4@0+ (1,0) [0|255] "" XXX
 SG_ NEW_SIGNAL_7 : 38|1@0+ (1,0) [0|1] "" XXX
 SG_ NEW_SIGNAL_8 : 39|1@0+ (1,0) [0|1] "" XXX
 SG_ NEW_SIGNAL_9 : 53|14@0- (0.04,0) [-327.68|327.64] "" XXX
 SG_ NEW_SIGNAL_10 : 55|2@0+ (1,0) [0|3] "" XXX

BO_ 1567 R_0x61f: 8 XXX
 SG_ NEW_SIGNAL_1 : 7|8@0- (1,0) [-128|127] "" XXX
 SG_ NEW_SIGNAL_2 : 12|10@0- (0.2,0) [-102.4|102.2] "" XXX
 SG_ NEW_SIGNAL_3 : 15|3@0+ (1,0) [0|7] "" XXX
 SG_ NEW_SIGNAL_4 : 18|11@0+ (0.1,0) [0|204.7] "" XXX
 SG_ NEW_SIGNAL_5 : 33|10@0- (0.2,0) [-102.4|102.2] "" XXX
 SG_ NEW_SIGNAL_6 : 37|4@0+ (1,0) [0|255] "" XXX
 SG_ NEW_SIGNAL_7 : 38|1@0+ (1,0) [0|1] "" XXX
 SG_ NEW_SIGNAL_8 : 39|1@0+ (1,0) [0|1] "" XXX
 SG_ NEW_SIGNAL_9 : 53|14@0- (0.04,0) [-327.68|327.64] "" XXX
 SG_ NEW_SIGNAL_10 : 55|2@0+ (1,0) [0|3] "" XXX

BO_ 1568 R_0x620: 8 XXX
 SG_ NEW_SIGNAL_1 : 7|8@0- (1,0) [-128|127] "" XXX
 SG_ NEW_SIGNAL_2 : 12|10@0- (0.2,0) [-102.4|102.2] "" XXX
 SG_ NEW_SIGNAL_3 : 15|3@0+ (1,0) [0|7] "" XXX
 SG_ NEW_SIGNAL_4 : 18|11@0+ (0.1,0) [0|204.7] "" XXX
 SG_ NEW_SIGNAL_5 : 33|10@0- (0.2,0) [-102.4|102.2] "" XXX
 SG_ NEW_SIGNAL_6 : 37|4@0+ (1,0) [0|255] "" XXX
 SG_ NEW_SIGNAL_7 : 38|1@0+ (1,0) [0|1] "" XXX
 SG_ NEW_SIGNAL_8 : 39|1@0+ (1,0) [0|1] "" XXX
 SG_ NEW_SIGNAL_9 : 53|14@0- (0.04,0) [-327.68|327.64] "" XXX
 SG_ NEW_SIGNAL_10 : 55|2@0+ (1,0) [0|3] "" XXX

BO_ 1569 R_0x621: 8 XXX
 SG_ NEW_SIGNAL_1 : 7|8@0- (1,0) [-128|127] "" XXX
 SG_ NEW_SIGNAL_2 : 12|10@0- (0.2,0) [-102.4|102.2] "" XXX
 SG_ NEW_SIGNAL_3 : 15|3@0+ (1,0) [0|7] "" XXX
 SG_ NEW_SIGNAL_4 : 18|11@0+ (0.1,0) [0|204.7] "" XXX
 SG_ NEW_SIGNAL_5 : 33|10@0- (0.2,0) [-102.4|102.2] "" XXX
 SG_ NEW_SIGNAL_6 : 37|4@0+ (1,0) [0|255] "" XXX
 SG_ NEW_SIGNAL_7 : 38|1@0+ (1,0) [0|1] "" XXX
 SG_ NEW_SIGNAL_8 : 39|1@0+ (1,0) [0|1] "" XXX
 SG_ NEW_SIGNAL_9 : 53|14@0- (0.04,0) [-327.68|327.64] "" XXX
 SG_ NEW_SIGNAL_10 : 55|2@0+ (1,0) [0|3] "" XXX

BO_ 1570 R_0x622: 8 XXX
 SG_ NEW_SIGNAL_1 : 7|8@0- (1,0) [-128|127] "" XXX
 SG_ NEW_SIGNAL_2 : 12|10@0- (0.2,0) [-102.4|102.2] "" XXX
 SG_ NEW_SIGNAL_3 : 15|3@0+ (1,0) [0|7] "" XXX
 SG_ NEW_SIGNAL_4 : 18|11@0+ (0.1,0) [0|204.7] "" XXX
 SG_ NEW_SIGNAL_5 : 33|10@0- (0.2,0) [-102.4|102.2] "" XXX
 SG_ NEW_SIGNAL_6 : 37|4@0+ (1,0) [0|255] "" XXX
 SG_ NEW_SIGNAL_7 : 38|1@0+ (1,0) [0|1] "" XXX
 SG_ NEW_SIGNAL_8 : 39|1@0+ (1,0) [0|1] "" XXX
 SG_ NEW_SIGNAL_9 : 53|14@0- (0.04,0) [-327.68|327.64] "" XXX
 SG_ NEW_SIGNAL_10 : 55|2@0+ (1,0) [0|3] "" XXX

BO_ 1571 R_0x623: 8 XXX
 SG_ NEW_SIGNAL_1 : 7|8@0- (1,0) [-128|127] "" XXX
 SG_ NEW_SIGNAL_2 : 12|10@0- (0.2,0) [-102.4|102.2] "" XXX
 SG_ NEW_SIGNAL_3 : 15|3@0+ (1,0) [0|7] "" XXX
 SG_ NEW_SIGNAL_4 : 18|11@0+ (0.1,0) [0|204.7] "" XXX
 SG_ NEW_SIGNAL_5 : 33|10@0- (0.2,0) [-102.4|102.2] "" XXX
 SG_ NEW_SIGNAL_6 : 37|4@0+ (1,0) [0|255] "" XXX
 SG_ NEW_SIGNAL_7 : 38|1@0+ (1,0) [0|1] "" XXX
 SG_ NEW_SIGNAL_8 : 39|1@0+ (1,0) [0|1] "" XXX
 SG_ NEW_SIGNAL_9 : 53|14@0- (0.04,0) [-327.68|327.64] "" XXX
 SG_ NEW_SIGNAL_10 : 55|2@0+ (1,0) [0|3] "" XXX

BO_ 1572 R_0x624: 8 XXX
 SG_ NEW_SIGNAL_1 : 7|8@0- (1,0) [-128|127] "" XXX
 SG_ NEW_SIGNAL_2 : 12|10@0- (0.2,0) [-102.4|102.2] "" XXX
 SG_ NEW_SIGNAL_3 : 15|3@0+ (1,0) [0|7] "" XXX
 SG_ NEW_SIGNAL_4 : 18|11@0+ (0.1,0) [0|204.7] "" XXX
 SG_ NEW_SIGNAL_5 : 33|10@0- (0.2,0) [-102.4|102.2] "" XXX
 SG_ NEW_SIGNAL_6 : 37|4@0+ (1,0) [0|255] "" XXX
 SG_ NEW_SIGNAL_7 : 38|1@0+ (1,0) [0|1] "" XXX
 SG_ NEW_SIGNAL_8 : 39|1@0+ (1,0) [0|1] "" XXX
 SG_ NEW_SIGNAL_9 : 53|14@0- (0.04,0) [-327.68|327.64] "" XXX
 SG_ NEW_SIGNAL_10 : 55|2@0+ (1,0) [0|3] "" XXX

BO_ 1573 R_0x625: 8 XXX
 SG_ NEW_SIGNAL_1 : 7|8@0- (1,0) [-128|127] "" XXX
 SG_ NEW_SIGNAL_2 : 12|10@0- (0.2,0) [-102.4|102.2] "" XXX
 SG_ NEW_SIGNAL_3 : 15|3@0+ (1,0) [0|7] "" XXX
 SG_ NEW_SIGNAL_4 : 18|11@0+ (0.1,0) [0|204.7] "" XXX
 SG_ NEW_SIGNAL_5 : 33|10@0- (0.2,0) [-102.4|102.2] "" XXX
 SG_ NEW_SIGNAL_6 : 37|4@0+ (1,0) [0|255] "" XXX
 SG_ NEW_SIGNAL_7 : 38|1@0+ (1,0) [0|1] "" XXX
 SG_ NEW_SIGNAL_8 : 39|1@0+ (1,0) [0|1] "" XXX
 SG_ NEW_SIGNAL_9 : 53|14@0- (0.04,0) [-327.68|327.64] "" XXX
 SG_ NEW_SIGNAL_10 : 55|2@0+ (1,0) [0|3] "" XXX

BO_ 1574 R_0x626: 8 XXX
 SG_ NEW_SIGNAL_1 : 7|8@0- (1,0) [-128|127] "" XXX
 SG_ NEW_SIGNAL_2 : 12|10@0- (0.2,0) [-102.4|102.2] "" XXX
 SG_ NEW_SIGNAL_3 : 15|3@0+ (1,0) [0|7] "" XXX
 SG_ NEW_SIGNAL_4 : 18|11@0+ (0.1,0) [0|204.7] "" XXX
 SG_ NEW_SIGNAL_5 : 33|10@0- (0.2,0) [-102.4|102.2] "" XXX
 SG_ NEW_SIGNAL_6 : 37|4@0+ (1,0) [0|255] "" XXX
 SG_ NEW_SIGNAL_7 : 38|1@0+ (1,0) [0|1] "" XXX
 SG_ NEW_SIGNAL_8 : 39|1@0+ (1,0) [0|1] "" XXX
 SG_ NEW_SIGNAL_9 : 53|14@0- (0.04,0) [-327.68|327.64] "" XXX
 SG_ NEW_SIGNAL_10 : 55|2@0+ (1,0) [0|3] "" XXX

BO_ 1575 R_0x627: 8 XXX
 SG_ NEW_SIGNAL_1 : 7|8@0- (1,0) [-128|127] "" XXX
 SG_ NEW_SIGNAL_2 : 12|10@0- (0.2,0) [-102.4|102.2] "" XXX
 SG_ NEW_SIGNAL_3 : 15|3@0+ (1,0) [0|7] "" XXX
 SG_ NEW_SIGNAL_4 : 18|11@0+ (0.1,0) [0|204.7] "" XXX
 SG_ NEW_SIGNAL_5 : 33|10@0- (0.2,0) [-102.4|102.2] "" XXX
 SG_ NEW_SIGNAL_6 : 37|4@0+ (1,0) [0|255] "" XXX
 SG_ NEW_SIGNAL_7 : 38|1@0+ (1,0) [0|1] "" XXX
 SG_ NEW_SIGNAL_8 : 39|1@0+ (1,0) [0|1] "" XXX
 SG_ NEW_SIGNAL_9 : 53|14@0- (0.04,0) [-327.68|327.64] "" XXX
 SG_ NEW_SIGNAL_10 : 55|2@0+ (1,0) [0|3] "" XXX

BO_ 1576 R_0x628: 8 XXX
 SG_ NEW_SIGNAL_1 : 7|8@0- (1,0) [-128|127] "" XXX
 SG_ NEW_SIGNAL_2 : 12|10@0- (0.2,0) [-102.4|102.2] "" XXX
 SG_ NEW_SIGNAL_3 : 15|3@0+ (1,0) [0|7] "" XXX
 SG_ NEW_SIGNAL_4 : 18|11@0+ (0.1,0) [0|204.7] "" XXX
 SG_ NEW_SIGNAL_5 : 33|10@0- (0.2,0) [-102.4|102.2] "" XXX
 SG_ NEW_SIGNAL_6 : 37|4@0+ (1,0) [0|255] "" XXX
 SG_ NEW_SIGNAL_7 : 38|1@0+ (1,0) [0|1] "" XXX
 SG_ NEW_SIGNAL_8 : 39|1@0+ (1,0) [0|1] "" XXX
 SG_ NEW_SIGNAL_9 : 53|14@0- (0.04,0) [-327.68|327.64] "" XXX
 SG_ NEW_SIGNAL_10 : 55|2@0+ (1,0) [0|3] "" XXX

BO_ 1577 R_0x629: 8 XXX
 SG_ NEW_SIGNAL_1 : 7|8@0- (1,0) [-128|127] "" XXX
 SG_ NEW_SIGNAL_2 : 12|10@0- (0.2,0) [-102.4|102.2] "" XXX
 SG_ NEW_SIGNAL_3 : 15|3@0+ (1,0) [0|7] "" XXX
 SG_ NEW_SIGNAL_4 : 18|11@0+ (0.1,0) [0|204.7] "" XXX
 SG_ NEW_SIGNAL_5 : 33|10@0- (0.2,0) [-102.4|102.2] "" XXX
 SG_ NEW_SIGNAL_6 : 37|4@0+ (1,0) [0|255] "" XXX
 SG_ NEW_SIGNAL_7 : 38|1@0+ (1,0) [0|1] "" XXX
 SG_ NEW_SIGNAL_8 : 39|1@0+ (1,0) [0|1] "" XXX
 SG_ NEW_SIGNAL_9 : 53|14@0- (0.04,0) [-327.68|327.64] "" XXX
 SG_ NEW_SIGNAL_10 : 55|2@0+ (1,0) [0|3] "" XXX

BO_ 1578 R_0x62a: 8 XXX
 SG_ NEW_SIGNAL_1 : 7|8@0- (1,0) [-128|127] "" XXX
 SG_ NEW_SIGNAL_2 : 12|10@0- (0.2,0) [-102.4|102.2] "" XXX
 SG_ NEW_SIGNAL_3 : 15|3@0+ (1,0) [0|7] "" XXX
 SG_ NEW_SIGNAL_4 : 18|11@0+ (0.1,0) [0|204.7] "" XXX
 SG_ NEW_SIGNAL_5 : 33|10@0- (0.2,0) [-102.4|102.2] "" XXX
 SG_ NEW_SIGNAL_6 : 37|4@0+ (1,0) [0|255] "" XXX
 SG_ NEW_SIGNAL_7 : 38|1@0+ (1,0) [0|1] "" XXX
 SG_ NEW_SIGNAL_8 : 39|1@0+ (1,0) [0|1] "" XXX
 SG_ NEW_SIGNAL_9 : 53|14@0- (0.04,0) [-327.68|327.64] "" XXX
 SG_ NEW_SIGNAL_10 : 55|2@0+ (1,0) [0|3] "" XXX

BO_ 1579 R_0x62b: 8 XXX
 SG_ NEW_SIGNAL_1 : 7|8@0- (1,0) [-128|127] "" XXX
 SG_ NEW_SIGNAL_2 : 12|10@0- (0.2,0) [-102.4|102.2] "" XXX
 SG_ NEW_SIGNAL_3 : 15|3@0+ (1,0) [0|7] "" XXX
 SG_ NEW_SIGNAL_4 : 18|11@0+ (0.1,0) [0|204.7] "" XXX
 SG_ NEW_SIGNAL_5 : 33|10@0- (0.2,0) [-102.4|102.2] "" XXX
 SG_ NEW_SIGNAL_6 : 37|4@0+ (1,0) [0|255] "" XXX
 SG_ NEW_SIGNAL_7 : 38|1@0+ (1,0) [0|1] "" XXX
 SG_ NEW_SIGNAL_8 : 39|1@0+ (1,0) [0|1] "" XXX
 SG_ NEW_SIGNAL_9 : 53|14@0- (0.04,0) [-327.68|327.64] "" XXX
 SG_ NEW_SIGNAL_10 : 55|2@0+ (1,0) [0|3] "" XXX

BO_ 1580 R_0x62c: 8 XXX
 SG_ NEW_SIGNAL_1 : 7|8@0- (1,0) [-128|127] "" XXX
 SG_ NEW_SIGNAL_2 : 12|10@0- (0.2,0) [-102.4|102.2] "" XXX
 SG_ NEW_SIGNAL_3 : 15|3@0+ (1,0) [0|7] "" XXX
 SG_ NEW_SIGNAL_4 : 18|11@0+ (0.1,0) [0|204.7] "" XXX
 SG_ NEW_SIGNAL_5 : 33|10@0- (0.2,0) [-102.4|102.2] "" XXX
 SG_ NEW_SIGNAL_6 : 37|4@0+ (1,0) [0|255] "" XXX
 SG_ NEW_SIGNAL_7 : 38|1@0+ (1,0) [0|1] "" XXX
 SG_ NEW_SIGNAL_8 : 39|1@0+ (1,0) [0|1] "" XXX
 SG_ NEW_SIGNAL_9 : 53|14@0- (0.04,0) [-327.68|327.64] "" XXX
 SG_ NEW_SIGNAL_10 : 55|2@0+ (1,0) [0|3] "" XXX

BO_ 1581 R_0x62d: 8 XXX
 SG_ NEW_SIGNAL_1 : 7|8@0- (1,0) [-128|127] "" XXX
 SG_ NEW_SIGNAL_2 : 12|10@0- (0.2,0) [-102.4|102.2] "" XXX
 SG_ NEW_SIGNAL_3 : 15|3@0+ (1,0) [0|7] "" XXX
 SG_ NEW_SIGNAL_4 : 18|11@0+ (0.1,0) [0|204.7] "" XXX
 SG_ NEW_SIGNAL_5 : 33|10@0- (0.2,0) [-102.4|102.2] "" XXX
 SG_ NEW_SIGNAL_6 : 37|4@0+ (1,0) [0|255] "" XXX
 SG_ NEW_SIGNAL_7 : 38|1@0+ (1,0) [0|1] "" XXX
 SG_ NEW_SIGNAL_8 : 39|1@0+ (1,0) [0|1] "" XXX
 SG_ NEW_SIGNAL_9 : 53|14@0- (0.04,0) [-327.68|327.64] "" XXX
 SG_ NEW_SIGNAL_10 : 55|2@0+ (1,0) [0|3] "" XXX

BO_ 1582 R_0x62e: 8 XXX
 SG_ NEW_SIGNAL_1 : 7|8@0- (1,0) [-128|127] "" XXX
 SG_ NEW_SIGNAL_2 : 12|10@0- (0.2,0) [-102.4|102.2] "" XXX
 SG_ NEW_SIGNAL_3 : 15|3@0+ (1,0) [0|7] "" XXX
 SG_ NEW_SIGNAL_4 : 18|11@0+ (0.1,0) [0|204.7] "" XXX
 SG_ NEW_SIGNAL_5 : 33|10@0- (0.2,0) [-102.4|102.2] "" XXX
 SG_ NEW_SIGNAL_6 : 37|4@0+ (1,0) [0|255] "" XXX
 SG_ NEW_SIGNAL_7 : 38|1@0+ (1,0) [0|1] "" XXX
 SG_ NEW_SIGNAL_8 : 39|1@0+ (1,0) [0|1] "" XXX
 SG_ NEW_SIGNAL_9 : 53|14@0- (0.04,0) [-327.68|327.64] "" XXX
 SG_ NEW_SIGNAL_10 : 55|2@0+ (1,0) [0|3] "" XXX

BO_ 1583 R_0x62f: 8 XXX
 SG_ NEW_SIGNAL_1 : 7|8@0- (1,0) [-128|127] "" XXX
 SG_ NEW_SIGNAL_2 : 12|10@0- (0.2,0) [-102.4|102.2] "" XXX
 SG_ NEW_SIGNAL_3 : 15|3@0+ (1,0) [0|7] "" XXX
 SG_ NEW_SIGNAL_4 : 18|11@0+ (0.1,0) [0|204.7] "" XXX
 SG_ NEW_SIGNAL_5 : 33|10@0- (0.2,0) [-102.4|102.2] "" XXX
 SG_ NEW_SIGNAL_6 : 37|4@0+ (1,0) [0|255] "" XXX
 SG_ NEW_SIGNAL_7 : 38|1@0+ (1,0) [0|1] "" XXX
 SG_ NEW_SIGNAL_8 : 39|1@0+ (1,0) [0|1] "" XXX
 SG_ NEW_SIGNAL_9 : 53|14@0- (0.04,0) [-327.68|327.64] "" XXX
 SG_ NEW_SIGNAL_10 : 55|2@0+ (1,0) [0|3] "" XXX

BO_ 1584 R_0x630: 8 XXX
 SG_ NEW_SIGNAL_1 : 7|8@0- (1,0) [-128|127] "" XXX
 SG_ NEW_SIGNAL_2 : 12|10@0- (0.2,0) [-102.4|102.2] "" XXX
 SG_ NEW_SIGNAL_3 : 15|3@0+ (1,0) [0|7] "" XXX
 SG_ NEW_SIGNAL_4 : 18|11@0+ (0.1,0) [0|204.7] "" XXX
 SG_ NEW_SIGNAL_5 : 33|10@0- (0.2,0) [-102.4|102.2] "" XXX
 SG_ NEW_SIGNAL_6 : 37|4@0+ (1,0) [0|255] "" XXX
 SG_ NEW_SIGNAL_7 : 38|1@0+ (1,0) [0|1] "" XXX
 SG_ NEW_SIGNAL_8 : 39|1@0+ (1,0) [0|1] "" XXX
 SG_ NEW_SIGNAL_9 : 53|14@0- (0.04,0) [-327.68|327.64] "" XXX
 SG_ NEW_SIGNAL_10 : 55|2@0+ (1,0) [0|3] "" XXX

BO_ 1585 R_0x631: 8 XXX
 SG_ NEW_SIGNAL_1 : 7|8@0- (1,0) [-128|127] "" XXX
 SG_ NEW_SIGNAL_2 : 12|10@0- (0.2,0) [-102.4|102.2] "" XXX
 SG_ NEW_SIGNAL_3 : 15|3@0+ (1,0) [0|7] "" XXX
 SG_ NEW_SIGNAL_4 : 18|11@0+ (0.1,0) [0|204.7] "" XXX
 SG_ NEW_SIGNAL_5 : 33|10@0- (0.2,0) [-102.4|102.2] "" XXX
 SG_ NEW_SIGNAL_6 : 37|4@0+ (1,0) [0|255] "" XXX
 SG_ NEW_SIGNAL_7 : 38|1@0+ (1,0) [0|1] "" XXX
 SG_ NEW_SIGNAL_8 : 39|1@0+ (1,0) [0|1] "" XXX
 SG_ NEW_SIGNAL_9 : 53|14@0- (0.04,0) [-327.68|327.64] "" XXX
 SG_ NEW_SIGNAL_10 : 55|2@0+ (1,0) [0|3] "" XXX

BO_ 1586 R_0x632: 8 XXX
 SG_ NEW_SIGNAL_1 : 7|8@0- (1,0) [-128|127] "" XXX
 SG_ NEW_SIGNAL_2 : 12|10@0- (0.2,0) [-102.4|102.2] "" XXX
 SG_ NEW_SIGNAL_3 : 15|3@0+ (1,0) [0|7] "" XXX
 SG_ NEW_SIGNAL_4 : 18|11@0+ (0.1,0) [0|204.7] "" XXX
 SG_ NEW_SIGNAL_5 : 33|10@0- (0.2,0) [-102.4|102.2] "" XXX
 SG_ NEW_SIGNAL_6 : 37|4@0+ (1,0) [0|255] "" XXX
 SG_ NEW_SIGNAL_7 : 38|1@0+ (1,0) [0|1] "" XXX
 SG_ NEW_SIGNAL_8 : 39|1@0+ (1,0) [0|1] "" XXX
 SG_ NEW_SIGNAL_9 : 53|14@0- (0.04,0) [-327.68|327.64] "" XXX
 SG_ NEW_SIGNAL_10 : 55|2@0+ (1,0) [0|3] "" XXX

BO_ 1587 R_0x633: 8 XXX
 SG_ NEW_SIGNAL_1 : 7|8@0- (1,0) [-128|127] "" XXX
 SG_ NEW_SIGNAL_2 : 12|10@0- (0.2,0) [-102.4|102.2] "" XXX
 SG_ NEW_SIGNAL_3 : 15|3@0+ (1,0) [0|7] "" XXX
 SG_ NEW_SIGNAL_4 : 18|11@0+ (0.1,0) [0|204.7] "" XXX
 SG_ NEW_SIGNAL_5 : 33|10@0- (0.2,0) [-102.4|102.2] "" XXX
 SG_ NEW_SIGNAL_6 : 37|4@0+ (1,0) [0|255] "" XXX
 SG_ NEW_SIGNAL_7 : 38|1@0+ (1,0) [0|1] "" XXX
 SG_ NEW_SIGNAL_8 : 39|1@0+ (1,0) [0|1] "" XXX
 SG_ NEW_SIGNAL_9 : 53|14@0- (0.04,0) [-327.68|327.64] "" XXX
 SG_ NEW_SIGNAL_10 : 55|2@0+ (1,0) [0|3] "" XXX

BO_ 1588 R_0x634: 8 XXX
 SG_ NEW_SIGNAL_1 : 7|8@0- (1,0) [-128|127] "" XXX
 SG_ NEW_SIGNAL_2 : 12|10@0- (0.2,0) [-102.4|102.2] "" XXX
 SG_ NEW_SIGNAL_3 : 15|3@0+ (1,0) [0|7] "" XXX
 SG_ NEW_SIGNAL_4 : 18|11@0+ (0.1,0) [0|204.7] "" XXX
 SG_ NEW_SIGNAL_5 : 33|10@0- (0.2,0) [-102.4|102.2] "" XXX
 SG_ NEW_SIGNAL_6 : 37|4@0+ (1,0) [0|255] "" XXX
 SG_ NEW_SIGNAL_7 : 38|1@0+ (1,0) [0|1] "" XXX
 SG_ NEW_SIGNAL_8 : 39|1@0+ (1,0) [0|1] "" XXX
 SG_ NEW_SIGNAL_9 : 53|14@0- (0.04,0) [-327.68|327.64] "" XXX
 SG_ NEW_SIGNAL_10 : 55|2@0+ (1,0) [0|3] "" XXX

BO_ 1589 R_0x635: 8 XXX
 SG_ NEW_SIGNAL_1 : 7|8@0- (1,0) [-128|127] "" XXX
 SG_ NEW_SIGNAL_2 : 12|10@0- (0.2,0) [-102.4|102.2] "" XXX
 SG_ NEW_SIGNAL_3 : 15|3@0+ (1,0) [0|7] "" XXX
 SG_ NEW_SIGNAL_4 : 18|11@0+ (0.1,0) [0|204.7] "" XXX
 SG_ NEW_SIGNAL_5 : 33|10@0- (0.2,0) [-102.4|102.2] "" XXX
 SG_ NEW_SIGNAL_6 : 37|4@0+ (1,0) [0|255] "" XXX
 SG_ NEW_SIGNAL_7 : 38|1@0+ (1,0) [0|1] "" XXX
 SG_ NEW_SIGNAL_8 : 39|1@0+ (1,0) [0|1] "" XXX
 SG_ NEW_SIGNAL_9 : 53|14@0- (0.04,0) [-327.68|327.64] "" XXX
 SG_ NEW_SIGNAL_10 : 55|2@0+ (1,0) [0|3] "" XXX

BO_ 1590 R_0x636: 8 XXX
 SG_ NEW_SIGNAL_1 : 7|8@0- (1,0) [-128|127] "" XXX
 SG_ NEW_SIGNAL_2 : 12|10@0- (0.2,0) [-102.4|102.2] "" XXX
 SG_ NEW_SIGNAL_3 : 15|3@0+ (1,0) [0|7] "" XXX
 SG_ NEW_SIGNAL_4 : 18|11@0+ (0.1,0) [0|204.7] "" XXX
 SG_ NEW_SIGNAL_5 : 33|10@0- (0.2,0) [-102.4|102.2] "" XXX
 SG_ NEW_SIGNAL_6 : 37|4@0+ (1,0) [0|255] "" XXX
 SG_ NEW_SIGNAL_7 : 38|1@0+ (1,0) [0|1] "" XXX
 SG_ NEW_SIGNAL_8 : 39|1@0+ (1,0) [0|1] "" XXX
 SG_ NEW_SIGNAL_9 : 53|14@0- (0.04,0) [-327.68|327.64] "" XXX
 SG_ NEW_SIGNAL_10 : 55|2@0+ (1,0) [0|3] "" XXX

BO_ 1591 R_0x637: 8 XXX
 SG_ NEW_SIGNAL_1 : 7|8@0- (1,0) [-128|127] "" XXX
 SG_ NEW_SIGNAL_2 : 12|10@0- (0.2,0) [-102.4|102.2] "" XXX
 SG_ NEW_SIGNAL_3 : 15|3@0+ (1,0) [0|7] "" XXX
 SG_ NEW_SIGNAL_4 : 18|11@0+ (0.1,0) [0|204.7] "" XXX
 SG_ NEW_SIGNAL_5 : 33|10@0- (0.2,0) [-102.4|102.2] "" XXX
 SG_ NEW_SIGNAL_6 : 37|4@0+ (1,0) [0|255] "" XXX
 SG_ NEW_SIGNAL_7 : 38|1@0+ (1,0) [0|1] "" XXX
 SG_ NEW_SIGNAL_8 : 39|1@0+ (1,0) [0|1] "" XXX
 SG_ NEW_SIGNAL_9 : 53|14@0- (0.04,0) [-327.68|327.64] "" XXX
 SG_ NEW_SIGNAL_10 : 55|2@0+ (1,0) [0|3] "" XXX

BO_ 1592 R_0x638: 8 XXX
 SG_ NEW_SIGNAL_1 : 7|8@0- (1,0) [-128|127] "" XXX
 SG_ NEW_SIGNAL_2 : 12|10@0- (0.2,0) [-102.4|102.2] "" XXX
 SG_ NEW_SIGNAL_3 : 15|3@0+ (1,0) [0|7] "" XXX
 SG_ NEW_SIGNAL_4 : 18|11@0+ (0.1,0) [0|204.7] "" XXX
 SG_ NEW_SIGNAL_5 : 33|10@0- (0.2,0) [-102.4|102.2] "" XXX
 SG_ NEW_SIGNAL_6 : 37|4@0+ (1,0) [0|255] "" XXX
 SG_ NEW_SIGNAL_7 : 38|1@0+ (1,0) [0|1] "" XXX
 SG_ NEW_SIGNAL_8 : 39|1@0+ (1,0) [0|1] "" XXX
 SG_ NEW_SIGNAL_9 : 53|14@0- (0.04,0) [-327.68|327.64] "" XXX
 SG_ NEW_SIGNAL_10 : 55|2@0+ (1,0) [0|3] "" XXX

BO_ 1593 R_0x639: 8 XXX
 SG_ NEW_SIGNAL_1 : 7|8@0- (1,0) [-128|127] "" XXX
 SG_ NEW_SIGNAL_2 : 12|10@0- (0.2,0) [-102.4|102.2] "" XXX
 SG_ NEW_SIGNAL_3 : 15|3@0+ (1,0) [0|7] "" XXX
 SG_ NEW_SIGNAL_4 : 18|11@0+ (0.1,0) [0|204.7] "" XXX
 SG_ NEW_SIGNAL_5 : 33|10@0- (0.2,0) [-102.4|102.2] "" XXX
 SG_ NEW_SIGNAL_6 : 37|4@0+ (1,0) [0|255] "" XXX
 SG_ NEW_SIGNAL_7 : 38|1@0+ (1,0) [0|1] "" XXX
 SG_ NEW_SIGNAL_8 : 39|1@0+ (1,0) [0|1] "" XXX
 SG_ NEW_SIGNAL_9 : 53|14@0- (0.04,0) [-327.68|327.64] "" XXX
 SG_ NEW_SIGNAL_10 : 55|2@0+ (1,0) [0|3] "" XXX

BO_ 1594 R_0x63a: 8 XXX
 SG_ NEW_SIGNAL_1 : 7|8@0- (1,0) [-128|127] "" XXX
 SG_ NEW_SIGNAL_2 : 12|10@0- (0.2,0) [-102.4|102.2] "" XXX
 SG_ NEW_SIGNAL_3 : 15|3@0+ (1,0) [0|7] "" XXX
 SG_ NEW_SIGNAL_4 : 18|11@0+ (0.1,0) [0|204.7] "" XXX
 SG_ NEW_SIGNAL_5 : 33|10@0- (0.2,0) [-102.4|102.2] "" XXX
 SG_ NEW_SIGNAL_6 : 37|4@0+ (1,0) [0|255] "" XXX
 SG_ NEW_SIGNAL_7 : 38|1@0+ (1,0) [0|1] "" XXX
 SG_ NEW_SIGNAL_8 : 39|1@0+ (1,0) [0|1] "" XXX
 SG_ NEW_SIGNAL_9 : 53|14@0- (0.04,0) [-327.68|327.64] "" XXX
 SG_ NEW_SIGNAL_10 : 55|2@0+ (1,0) [0|3] "" XXX

BO_ 1595 R_0x63b: 8 XXX
 SG_ NEW_SIGNAL_1 : 7|8@0- (1,0) [-128|127] "" XXX
 SG_ NEW_SIGNAL_2 : 12|10@0- (0.2,0) [-102.4|102.2] "" XXX
 SG_ NEW_SIGNAL_3 : 15|3@0+ (1,0) [0|7] "" XXX
 SG_ NEW_SIGNAL_4 : 18|11@0+ (0.1,0) [0|204.7] "" XXX
 SG_ NEW_SIGNAL_5 : 33|10@0- (0.2,0) [-102.4|102.2] "" XXX
 SG_ NEW_SIGNAL_6 : 37|4@0+ (1,0) [0|255] "" XXX
 SG_ NEW_SIGNAL_7 : 38|1@0+ (1,0) [0|1] "" XXX
 SG_ NEW_SIGNAL_8 : 39|1@0+ (1,0) [0|1] "" XXX
 SG_ NEW_SIGNAL_9 : 53|14@0- (0.04,0) [-327.68|327.64] "" XXX
 SG_ NEW_SIGNAL_10 : 55|2@0+ (1,0) [0|3] "" XXX

BO_ 1596 R_0x63c: 8 XXX
 SG_ NEW_SIGNAL_1 : 7|8@0- (1,0) [-128|127] "" XXX
 SG_ NEW_SIGNAL_2 : 12|10@0- (0.2,0) [-102.4|102.2] "" XXX
 SG_ NEW_SIGNAL_3 : 15|3@0+ (1,0) [0|7] "" XXX
 SG_ NEW_SIGNAL_4 : 18|11@0+ (0.1,0) [0|204.7] "" XXX
 SG_ NEW_SIGNAL_5 : 33|10@0- (0.2,0) [-102.4|102.2] "" XXX
 SG_ NEW_SIGNAL_6 : 37|4@0+ (1,0) [0|255] "" XXX
 SG_ NEW_SIGNAL_7 : 38|1@0+ (1,0) [0|1] "" XXX
 SG_ NEW_SIGNAL_8 : 39|1@0+ (1,0) [0|1] "" XXX
 SG_ NEW_SIGNAL_9 : 53|14@0- (0.04,0) [-327.68|327.64] "" XXX
 SG_ NEW_SIGNAL_10 : 55|2@0+ (1,0) [0|3] "" XXX

BO_ 1597 R_0x63d: 8 XXX
 SG_ NEW_SIGNAL_1 : 7|8@0- (1,0) [-128|127] "" XXX
 SG_ NEW_SIGNAL_2 : 12|10@0- (0.2,0) [-102.4|102.2] "" XXX
 SG_ NEW_SIGNAL_3 : 15|3@0+ (1,0) [0|7] "" XXX
 SG_ NEW_SIGNAL_4 : 18|11@0+ (0.1,0) [0|204.7] "" XXX
 SG_ NEW_SIGNAL_5 : 33|10@0- (0.2,0) [-102.4|102.2] "" XXX
 SG_ NEW_SIGNAL_6 : 37|4@0+ (1,0) [0|255] "" XXX
 SG_ NEW_SIGNAL_7 : 38|1@0+ (1,0) [0|1] "" XXX
 SG_ NEW_SIGNAL_8 : 39|1@0+ (1,0) [0|1] "" XXX
 SG_ NEW_SIGNAL_9 : 53|14@0- (0.04,0) [-327.68|327.64] "" XXX
 SG_ NEW_SIGNAL_10 : 55|2@0+ (1,0) [0|3] "" XXX

BO_ 1598 R_0x63e: 8 XXX
 SG_ NEW_SIGNAL_1 : 7|8@0- (1,0) [-128|127] "" XXX
 SG_ NEW_SIGNAL_2 : 12|10@0- (0.2,0) [-102.4|102.2] "" XXX
 SG_ NEW_SIGNAL_3 : 15|3@0+ (1,0) [0|7] "" XXX
 SG_ NEW_SIGNAL_4 : 18|11@0+ (0.1,0) [0|204.7] "" XXX
 SG_ NEW_SIGNAL_5 : 33|10@0- (0.2,0) [-102.4|102.2] "" XXX
 SG_ NEW_SIGNAL_6 : 37|4@0+ (1,0) [0|255] "" XXX
 SG_ NEW_SIGNAL_7 : 38|1@0+ (1,0) [0|1] "" XXX
 SG_ NEW_SIGNAL_8 : 39|1@0+ (1,0) [0|1] "" XXX
 SG_ NEW_SIGNAL_9 : 53|14@0- (0.04,0) [-327.68|327.64] "" XXX
 SG_ NEW_SIGNAL_10 : 55|2@0+ (1,0) [0|3] "" XXX

BO_ 1599 R_0x63f: 8 XXX
 SG_ NEW_SIGNAL_1 : 7|8@0- (1,0) [-128|127] "" XXX
 SG_ NEW_SIGNAL_2 : 12|10@0- (0.2,0) [-102.4|102.2] "" XXX
 SG_ NEW_SIGNAL_3 : 15|3@0+ (1,0) [0|7] "" XXX
 SG_ NEW_SIGNAL_4 : 18|11@0+ (0.1,0) [0|204.7] "" XXX
 SG_ NEW_SIGNAL_5 : 33|10@0- (0.2,0) [-102.4|102.2] "" XXX
 SG_ NEW_SIGNAL_6 : 37|4@0+ (1,0) [0|255] "" XXX
 SG_ NEW_SIGNAL_7 : 38|1@0+ (1,0) [0|1] "" XXX
 SG_ NEW_SIGNAL_8 : 39|1@0+ (1,0) [0|1] "" XXX
 SG_ NEW_SIGNAL_9 : 53|14@0- (0.04,0) [-327.68|327.64] "" XXX
 SG_ NEW_SIGNAL_10 : 55|2@0+ (1,0) [0|3] "" XXX

BO_ 1600 R_0x640: 8 XXX
 SG_ NEW_SIGNAL_1 : 7|8@0- (1,0) [-128|127] "" XXX
 SG_ NEW_SIGNAL_2 : 12|10@0- (0.2,0) [-102.4|102.2] "" XXX
 SG_ NEW_SIGNAL_3 : 15|3@0+ (1,0) [0|7] "" XXX
 SG_ NEW_SIGNAL_4 : 18|11@0+ (0.1,0) [0|204.7] "" XXX
 SG_ NEW_SIGNAL_5 : 33|10@0- (0.2,0) [-102.4|102.2] "" XXX
 SG_ NEW_SIGNAL_6 : 37|4@0+ (1,0) [0|255] "" XXX
 SG_ NEW_SIGNAL_7 : 38|1@0+ (1,0) [0|1] "" XXX
 SG_ NEW_SIGNAL_8 : 39|1@0+ (1,0) [0|1] "" XXX
 SG_ NEW_SIGNAL_9 : 53|14@0- (0.04,0) [-327.68|327.64] "" XXX
 SG_ NEW_SIGNAL_10 : 55|2@0+ (1,0) [0|3] "" XXX

BO_ 1601 R_0x641: 8 XXX
 SG_ NEW_SIGNAL_1 : 7|8@0- (1,0) [-128|127] "" XXX
 SG_ NEW_SIGNAL_2 : 12|10@0- (0.2,0) [-102.4|102.2] "" XXX
 SG_ NEW_SIGNAL_3 : 15|3@0+ (1,0) [0|7] "" XXX
 SG_ NEW_SIGNAL_4 : 18|11@0+ (0.1,0) [0|204.7] "" XXX
 SG_ NEW_SIGNAL_5 : 33|10@0- (0.2,0) [-102.4|102.2] "" XXX
 SG_ NEW_SIGNAL_6 : 37|4@0+ (1,0) [0|255] "" XXX
 SG_ NEW_SIGNAL_7 : 38|1@0+ (1,0) [0|1] "" XXX
 SG_ NEW_SIGNAL_8 : 39|1@0+ (1,0) [0|1] "" XXX
 SG_ NEW_SIGNAL_9 : 53|14@0- (0.04,0) [-327.68|327.64] "" XXX
 SG_ NEW_SIGNAL_10 : 55|2@0+ (1,0) [0|3] "" XXX

BO_ 1602 R_0x642: 8 XXX
 SG_ NEW_SIGNAL_1 : 7|8@0- (1,0) [-128|127] "" XXX
 SG_ NEW_SIGNAL_2 : 12|10@0- (0.2,0) [-102.4|102.2] "" XXX
 SG_ NEW_SIGNAL_3 : 15|3@0+ (1,0) [0|7] "" XXX
 SG_ NEW_SIGNAL_4 : 18|11@0+ (0.1,0) [0|204.7] "" XXX
 SG_ NEW_SIGNAL_5 : 33|10@0- (0.2,0) [-102.4|102.2] "" XXX
 SG_ NEW_SIGNAL_6 : 37|4@0+ (1,0) [0|255] "" XXX
 SG_ NEW_SIGNAL_7 : 38|1@0+ (1,0) [0|1] "" XXX
 SG_ NEW_SIGNAL_8 : 39|1@0+ (1,0) [0|1] "" XXX
 SG_ NEW_SIGNAL_9 : 53|14@0- (0.04,0) [-327.68|327.64] "" XXX
 SG_ NEW_SIGNAL_10 : 55|2@0+ (1,0) [0|3] "" XXX

BO_ 1603 R_0x643: 8 XXX
 SG_ NEW_SIGNAL_1 : 7|8@0- (1,0) [-128|127] "" XXX
 SG_ NEW_SIGNAL_2 : 12|10@0- (0.2,0) [-102.4|102.2] "" XXX
 SG_ NEW_SIGNAL_3 : 15|3@0+ (1,0) [0|7] "" XXX
 SG_ NEW_SIGNAL_4 : 18|11@0+ (0.1,0) [0|204.7] "" XXX
 SG_ NEW_SIGNAL_5 : 33|10@0- (0.2,0) [-102.4|102.2] "" XXX
 SG_ NEW_SIGNAL_6 : 37|4@0+ (1,0) [0|255] "" XXX
 SG_ NEW_SIGNAL_7 : 38|1@0+ (1,0) [0|1] "" XXX
 SG_ NEW_SIGNAL_8 : 39|1@0+ (1,0) [0|1] "" XXX
 SG_ NEW_SIGNAL_9 : 53|14@0- (0.04,0) [-327.68|327.64] "" XXX
 SG_ NEW_SIGNAL_10 : 55|2@0+ (1,0) [0|3] "" XXX

BO_ 1604 R_0x644: 8 XXX
 SG_ NEW_SIGNAL_1 : 7|8@0- (1,0) [-128|127] "" XXX
 SG_ NEW_SIGNAL_2 : 12|10@0- (0.2,0) [-102.4|102.2] "" XXX
 SG_ NEW_SIGNAL_3 : 15|3@0+ (1,0) [0|7] "" XXX
 SG_ NEW_SIGNAL_4 : 18|11@0+ (0.1,0) [0|204.7] "" XXX
 SG_ NEW_SIGNAL_5 : 33|10@0- (0.2,0) [-102.4|102.2] "" XXX
 SG_ NEW_SIGNAL_6 : 37|4@0+ (1,0) [0|255] "" XXX
 SG_ NEW_SIGNAL_7 : 38|1@0+ (1,0) [0|1] "" XXX
 SG_ NEW_SIGNAL_8 : 39|1@0+ (1,0) [0|1] "" XXX
 SG_ NEW_SIGNAL_9 : 53|14@0- (0.04,0) [-327.68|327.64] "" XXX
 SG_ NEW_SIGNAL_10 : 55|2@0+ (1,0) [0|3] "" XXX

BO_ 1605 R_0x645: 8 XXX
 SG_ NEW_SIGNAL_1 : 7|8@0- (1,0) [-128|127] "" XXX
 SG_ NEW_SIGNAL_2 : 12|10@0- (0.2,0) [-102.4|102.2] "" XXX
 SG_ NEW_SIGNAL_3 : 15|3@0+ (1,0) [0|7] "" XXX
 SG_ NEW_SIGNAL_4 : 18|11@0+ (0.1,0) [0|204.7] "" XXX
 SG_ NEW_SIGNAL_5 : 33|10@0- (0.2,0) [-102.4|102.2] "" XXX
 SG_ NEW_SIGNAL_6 : 37|4@0+ (1,0) [0|255] "" XXX
 SG_ NEW_SIGNAL_7 : 38|1@0+ (1,0) [0|1] "" XXX
 SG_ NEW_SIGNAL_8 : 39|1@0+ (1,0) [0|1] "" XXX
 SG_ NEW_SIGNAL_9 : 53|14@0- (0.04,0) [-327.68|327.64] "" XXX
 SG_ NEW_SIGNAL_10 : 55|2@0+ (1,0) [0|3] "" XXX

BO_ 1606 R_0x646: 8 XXX
 SG_ NEW_SIGNAL_1 : 7|8@0- (1,0) [-128|127] "" XXX
 SG_ NEW_SIGNAL_2 : 12|10@0- (0.2,0) [-102.4|102.2] "" XXX
 SG_ NEW_SIGNAL_3 : 15|3@0+ (1,0) [0|7] "" XXX
 SG_ NEW_SIGNAL_4 : 18|11@0+ (0.1,0) [0|204.7] "" XXX
 SG_ NEW_SIGNAL_5 : 33|10@0- (0.2,0) [-102.4|102.2] "" XXX
 SG_ NEW_SIGNAL_6 : 37|4@0+ (1,0) [0|255] "" XXX
 SG_ NEW_SIGNAL_7 : 38|1@0+ (1,0) [0|1] "" XXX
 SG_ NEW_SIGNAL_8 : 39|1@0+ (1,0) [0|1] "" XXX
 SG_ NEW_SIGNAL_9 : 53|14@0- (0.04,0) [-327.68|327.64] "" XXX
 SG_ NEW_SIGNAL_10 : 55|2@0+ (1,0) [0|3] "" XXX

BO_ 1607 R_0x647: 8 XXX
 SG_ NEW_SIGNAL_1 : 7|8@0- (1,0) [-128|127] "" XXX
 SG_ NEW_SIGNAL_2 : 12|10@0- (0.2,0) [-102.4|102.2] "" XXX
 SG_ NEW_SIGNAL_3 : 15|3@0+ (1,0) [0|7] "" XXX
 SG_ NEW_SIGNAL_4 : 18|11@0+ (0.1,0) [0|204.7] "" XXX
 SG_ NEW_SIGNAL_5 : 33|10@0- (0.2,0) [-102.4|102.2] "" XXX
 SG_ NEW_SIGNAL_6 : 37|4@0+ (1,0) [0|255] "" XXX
 SG_ NEW_SIGNAL_7 : 38|1@0+ (1,0) [0|1] "" XXX
 SG_ NEW_SIGNAL_8 : 39|1@0+ (1,0) [0|1] "" XXX
 SG_ NEW_SIGNAL_9 : 53|14@0- (0.04,0) [-327.68|327.64] "" XXX
 SG_ NEW_SIGNAL_10 : 55|2@0+ (1,0) [0|3] "" XXX

BO_ 1608 R_0x648: 8 XXX
 SG_ NEW_SIGNAL_1 : 7|8@0- (1,0) [-128|127] "" XXX
 SG_ NEW_SIGNAL_2 : 12|10@0- (0.2,0) [-102.4|102.2] "" XXX
 SG_ NEW_SIGNAL_3 : 15|3@0+ (1,0) [0|7] "" XXX
 SG_ NEW_SIGNAL_4 : 18|11@0+ (0.1,0) [0|204.7] "" XXX
 SG_ NEW_SIGNAL_5 : 33|10@0- (0.2,0) [-102.4|102.2] "" XXX
 SG_ NEW_SIGNAL_6 : 37|4@0+ (1,0) [0|255] "" XXX
 SG_ NEW_SIGNAL_7 : 38|1@0+ (1,0) [0|1] "" XXX
 SG_ NEW_SIGNAL_8 : 39|1@0+ (1,0) [0|1] "" XXX
 SG_ NEW_SIGNAL_9 : 53|14@0- (0.04,0) [-327.68|327.64] "" XXX
 SG_ NEW_SIGNAL_10 : 55|2@0+ (1,0) [0|3] "" XXX

BO_ 1609 R_0x649: 8 XXX
 SG_ NEW_SIGNAL_1 : 7|8@0- (1,0) [-128|127] "" XXX
 SG_ NEW_SIGNAL_2 : 12|10@0- (0.2,0) [-102.4|102.2] "" XXX
 SG_ NEW_SIGNAL_3 : 15|3@0+ (1,0) [0|7] "" XXX
 SG_ NEW_SIGNAL_4 : 18|11@0+ (0.1,0) [0|204.7] "" XXX
 SG_ NEW_SIGNAL_5 : 33|10@0- (0.2,0) [-102.4|102.2] "" XXX
 SG_ NEW_SIGNAL_6 : 37|4@0+ (1,0) [0|255] "" XXX
 SG_ NEW_SIGNAL_7 : 38|1@0+ (1,0) [0|1] "" XXX
 SG_ NEW_SIGNAL_8 : 39|1@0+ (1,0) [0|1] "" XXX
 SG_ NEW_SIGNAL_9 : 53|14@0- (0.04,0) [-327.68|327.64] "" XXX
 SG_ NEW_SIGNAL_10 : 55|2@0+ (1,0) [0|3] "" XXX

BO_ 1610 R_0x64a: 8 XXX
 SG_ NEW_SIGNAL_1 : 7|8@0- (1,0) [-128|127] "" XXX
 SG_ NEW_SIGNAL_2 : 12|10@0- (0.2,0) [-102.4|102.2] "" XXX
 SG_ NEW_SIGNAL_3 : 15|3@0+ (1,0) [0|7] "" XXX
 SG_ NEW_SIGNAL_4 : 18|11@0+ (0.1,0) [0|204.7] "" XXX
 SG_ NEW_SIGNAL_5 : 33|10@0- (0.2,0) [-102.4|102.2] "" XXX
 SG_ NEW_SIGNAL_6 : 37|4@0+ (1,0) [0|255] "" XXX
 SG_ NEW_SIGNAL_7 : 38|1@0+ (1,0) [0|1] "" XXX
 SG_ NEW_SIGNAL_8 : 39|1@0+ (1,0) [0|1] "" XXX
 SG_ NEW_SIGNAL_9 : 53|14@0- (0.04,0) [-327.68|327.64] "" XXX
 SG_ NEW_SIGNAL_10 : 55|2@0+ (1,0) [0|3] "" XXX

BO_ 1611 R_0x64b: 8 XXX
 SG_ NEW_SIGNAL_1 : 7|8@0- (1,0) [-128|127] "" XXX
 SG_ NEW_SIGNAL_2 : 12|10@0- (0.2,0) [-102.4|102.2] "" XXX
 SG_ NEW_SIGNAL_3 : 15|3@0+ (1,0) [0|7] "" XXX
 SG_ NEW_SIGNAL_4 : 18|11@0+ (0.1,0) [0|204.7] "" XXX
 SG_ NEW_SIGNAL_5 : 33|10@0- (0.2,0) [-102.4|102.2] "" XXX
 SG_ NEW_SIGNAL_6 : 37|4@0+ (1,0) [0|255] "" XXX
 SG_ NEW_SIGNAL_7 : 38|1@0+ (1,0) [0|1] "" XXX
 SG_ NEW_SIGNAL_8 : 39|1@0+ (1,0) [0|1] "" XXX
 SG_ NEW_SIGNAL_9 : 53|14@0- (0.04,0) [-327.68|327.64] "" XXX
 SG_ NEW_SIGNAL_10 : 55|2@0+ (1,0) [0|3] "" XXX

BO_ 1612 R_0x64c: 8 XXX
 SG_ NEW_SIGNAL_1 : 7|8@0- (1,0) [-128|127] "" XXX
 SG_ NEW_SIGNAL_2 : 12|10@0- (0.2,0) [-102.4|102.2] "" XXX
 SG_ NEW_SIGNAL_3 : 15|3@0+ (1,0) [0|7] "" XXX
 SG_ NEW_SIGNAL_4 : 18|11@0+ (0.1,0) [0|204.7] "" XXX
 SG_ NEW_SIGNAL_5 : 33|10@0- (0.2,0) [-102.4|102.2] "" XXX
 SG_ NEW_SIGNAL_6 : 37|4@0+ (1,0) [0|255] "" XXX
 SG_ NEW_SIGNAL_7 : 38|1@0+ (1,0) [0|1] "" XXX
 SG_ NEW_SIGNAL_8 : 39|1@0+ (1,0) [0|1] "" XXX
 SG_ NEW_SIGNAL_9 : 53|14@0- (0.04,0) [-327.68|327.64] "" XXX
 SG_ NEW_SIGNAL_10 : 55|2@0+ (1,0) [0|3] "" XXX

BO_ 1613 R_0x64d: 8 XXX
 SG_ NEW_SIGNAL_1 : 7|8@0- (1,0) [-128|127] "" XXX
 SG_ NEW_SIGNAL_2 : 12|10@0- (0.2,0) [-102.4|102.2] "" XXX
 SG_ NEW_SIGNAL_3 : 15|3@0+ (1,0) [0|7] "" XXX
 SG_ NEW_SIGNAL_4 : 18|11@0+ (0.1,0) [0|204.7] "" XXX
 SG_ NEW_SIGNAL_5 : 33|10@0- (0.2,0) [-102.4|102.2] "" XXX
 SG_ NEW_SIGNAL_6 : 37|4@0+ (1,0) [0|255] "" XXX
 SG_ NEW_SIGNAL_7 : 38|1@0+ (1,0) [0|1] "" XXX
 SG_ NEW_SIGNAL_8 : 39|1@0+ (1,0) [0|1] "" XXX
 SG_ NEW_SIGNAL_9 : 53|14@0- (0.04,0) [-327.68|327.64] "" XXX
 SG_ NEW_SIGNAL_10 : 55|2@0+ (1,0) [0|3] "" XXX

BO_ 1614 R_0x64e: 8 XXX
 SG_ NEW_SIGNAL_1 : 7|8@0- (1,0) [-128|127] "" XXX
 SG_ NEW_SIGNAL_2 : 12|10@0- (0.2,0) [-102.4|102.2] "" XXX
 SG_ NEW_SIGNAL_3 : 15|3@0+ (1,0) [0|7] "" XXX
 SG_ NEW_SIGNAL_4 : 18|11@0+ (0.1,0) [0|204.7] "" XXX
 SG_ NEW_SIGNAL_5 : 33|10@0- (0.2,0) [-102.4|102.2] "" XXX
 SG_ NEW_SIGNAL_6 : 37|4@0+ (1,0) [0|255] "" XXX
 SG_ NEW_SIGNAL_7 : 38|1@0+ (1,0) [0|1] "" XXX
 SG_ NEW_SIGNAL_8 : 39|1@0+ (1,0) [0|1] "" XXX
 SG_ NEW_SIGNAL_9 : 53|14@0- (0.04,0) [-327.68|327.64] "" XXX
 SG_ NEW_SIGNAL_10 : 55|2@0+ (1,0) [0|3] "" XXX

BO_ 1615 R_0x64f: 8 XXX
 SG_ NEW_SIGNAL_1 : 7|8@0- (1,0) [-128|127] "" XXX
 SG_ NEW_SIGNAL_2 : 12|10@0- (0.2,0) [-102.4|102.2] "" XXX
 SG_ NEW_SIGNAL_3 : 15|3@0+ (1,0) [0|7] "" XXX
 SG_ NEW_SIGNAL_4 : 18|11@0+ (0.1,0) [0|204.7] "" XXX
 SG_ NEW_SIGNAL_5 : 33|10@0- (0.2,0) [-102.4|102.2] "" XXX
 SG_ NEW_SIGNAL_6 : 37|4@0+ (1,0) [0|255] "" XXX
 SG_ NEW_SIGNAL_7 : 38|1@0+ (1,0) [0|1] "" XXX
 SG_ NEW_SIGNAL_8 : 39|1@0+ (1,0) [0|1] "" XXX
 SG_ NEW_SIGNAL_9 : 53|14@0- (0.04,0) [-327.68|327.64] "" XXX
 SG_ NEW_SIGNAL_10 : 55|2@0+ (1,0) [0|3] "" XXX

BO_ 1616 R_0x650: 8 XXX
 SG_ NEW_SIGNAL_1 : 7|8@0- (1,0) [-128|127] "" XXX
 SG_ NEW_SIGNAL_2 : 12|10@0- (0.2,0) [-102.4|102.2] "" XXX
 SG_ NEW_SIGNAL_3 : 15|3@0+ (1,0) [0|7] "" XXX
 SG_ NEW_SIGNAL_4 : 18|11@0+ (0.1,0) [0|204.7] "" XXX
 SG_ NEW_SIGNAL_5 : 33|10@0- (0.2,0) [-102.4|102.2] "" XXX
 SG_ NEW_SIGNAL_6 : 37|4@0+ (1,0) [0|255] "" XXX
 SG_ NEW_SIGNAL_7 : 38|1@0+ (1,0) [0|1] "" XXX
 SG_ NEW_SIGNAL_8 : 39|1@0+ (1,0) [0|1] "" XXX
 SG_ NEW_SIGNAL_9 : 53|14@0- (0.04,0) [-327.68|327.64] "" XXX
 SG_ NEW_SIGNAL_10 : 55|2@0+ (1,0) [0|3] "" XXX

BO_ 1617 R_0x651: 8 XXX
 SG_ NEW_SIGNAL_1 : 7|8@0- (1,0) [-128|127] "" XXX
 SG_ NEW_SIGNAL_2 : 12|10@0- (0.2,0) [-102.4|102.2] "" XXX
 SG_ NEW_SIGNAL_3 : 15|3@0+ (1,0) [0|7] "" XXX
 SG_ NEW_SIGNAL_4 : 18|11@0+ (0.1,0) [0|204.7] "" XXX
 SG_ NEW_SIGNAL_5 : 33|10@0- (0.2,0) [-102.4|102.2] "" XXX
 SG_ NEW_SIGNAL_6 : 37|4@0+ (1,0) [0|255] "" XXX
 SG_ NEW_SIGNAL_7 : 38|1@0+ (1,0) [0|1] "" XXX
 SG_ NEW_SIGNAL_8 : 39|1@0+ (1,0) [0|1] "" XXX
 SG_ NEW_SIGNAL_9 : 53|14@0- (0.04,0) [-327.68|327.64] "" XXX
 SG_ NEW_SIGNAL_10 : 55|2@0+ (1,0) [0|3] "" XXX

BO_ 1618 R_0x652: 8 XXX
 SG_ NEW_SIGNAL_1 : 7|8@0- (1,0) [-128|127] "" XXX
 SG_ NEW_SIGNAL_2 : 12|10@0- (0.2,0) [-102.4|102.2] "" XXX
 SG_ NEW_SIGNAL_3 : 15|3@0+ (1,0) [0|7] "" XXX
 SG_ NEW_SIGNAL_4 : 18|11@0+ (0.1,0) [0|204.7] "" XXX
 SG_ NEW_SIGNAL_5 : 33|10@0- (0.2,0) [-102.4|102.2] "" XXX
 SG_ NEW_SIGNAL_6 : 37|4@0+ (1,0) [0|255] "" XXX
 SG_ NEW_SIGNAL_7 : 38|1@0+ (1,0) [0|1] "" XXX
 SG_ NEW_SIGNAL_8 : 39|1@0+ (1,0) [0|1] "" XXX
 SG_ NEW_SIGNAL_9 : 53|14@0- (0.04,0) [-327.68|327.64] "" XXX
 SG_ NEW_SIGNAL_10 : 55|2@0+ (1,0) [0|3] "" XXX

BO_ 1619 R_0x653: 8 XXX
 SG_ NEW_SIGNAL_1 : 7|8@0- (1,0) [-128|127] "" XXX
 SG_ NEW_SIGNAL_2 : 12|10@0- (0.2,0) [-102.4|102.2] "" XXX
 SG_ NEW_SIGNAL_3 : 15|3@0+ (1,0) [0|7] "" XXX
 SG_ NEW_SIGNAL_4 : 18|11@0+ (0.1,0) [0|204.7] "" XXX
 SG_ NEW_SIGNAL_5 : 33|10@0- (0.2,0) [-102.4|102.2] "" XXX
 SG_ NEW_SIGNAL_6 : 37|4@0+ (1,0) [0|255] "" XXX
 SG_ NEW_SIGNAL_7 : 38|1@0+ (1,0) [0|1] "" XXX
 SG_ NEW_SIGNAL_8 : 39|1@0+ (1,0) [0|1] "" XXX
 SG_ NEW_SIGNAL_9 : 53|14@0- (0.04,0) [-327.68|327.64] "" XXX
 SG_ NEW_SIGNAL_10 : 55|2@0+ (1,0) [0|3] "" XXX

BO_ 1620 R_0x654: 8 XXX
 SG_ NEW_SIGNAL_1 : 7|8@0- (1,0) [-128|127] "" XXX
 SG_ NEW_SIGNAL_2 : 12|10@0- (0.2,0) [-102.4|102.2] "" XXX
 SG_ NEW_SIGNAL_3 : 15|3@0+ (1,0) [0|7] "" XXX
 SG_ NEW_SIGNAL_4 : 18|11@0+ (0.1,0) [0|204.7] "" XXX
 SG_ NEW_SIGNAL_5 : 33|10@0- (0.2,0) [-102.4|102.2] "" XXX
 SG_ NEW_SIGNAL_6 : 37|4@0+ (1,0) [0|255] "" XXX
 SG_ NEW_SIGNAL_7 : 38|1@0+ (1,0) [0|1] "" XXX
 SG_ NEW_SIGNAL_8 : 39|1@0+ (1,0) [0|1] "" XXX
 SG_ NEW_SIGNAL_9 : 53|14@0- (0.04,0) [-327.68|327.64] "" XXX
 SG_ NEW_SIGNAL_10 : 55|2@0+ (1,0) [0|3] "" XXX

BO_ 1621 R_0x655: 8 XXX
 SG_ NEW_SIGNAL_1 : 7|8@0- (1,0) [-128|127] "" XXX
 SG_ NEW_SIGNAL_2 : 12|10@0- (0.2,0) [-102.4|102.2] "" XXX
 SG_ NEW_SIGNAL_3 : 15|3@0+ (1,0) [0|7] "" XXX
 SG_ NEW_SIGNAL_4 : 18|11@0+ (0.1,0) [0|204.7] "" XXX
 SG_ NEW_SIGNAL_5 : 33|10@0- (0.2,0) [-102.4|102.2] "" XXX
 SG_ NEW_SIGNAL_6 : 37|4@0+ (1,0) [0|255] "" XXX
 SG_ NEW_SIGNAL_7 : 38|1@0+ (1,0) [0|1] "" XXX
 SG_ NEW_SIGNAL_8 : 39|1@0+ (1,0) [0|1] "" XXX
 SG_ NEW_SIGNAL_9 : 53|14@0- (0.04,0) [-327.68|327.64] "" XXX
 SG_ NEW_SIGNAL_10 : 55|2@0+ (1,0) [0|3] "" XXX

BO_ 1622 R_0x656: 8 XXX
 SG_ NEW_SIGNAL_1 : 7|8@0- (1,0) [-128|127] "" XXX
 SG_ NEW_SIGNAL_2 : 12|10@0- (0.2,0) [-102.4|102.2] "" XXX
 SG_ NEW_SIGNAL_3 : 15|3@0+ (1,0) [0|7] "" XXX
 SG_ NEW_SIGNAL_4 : 18|11@0+ (0.1,0) [0|204.7] "" XXX
 SG_ NEW_SIGNAL_5 : 33|10@0- (0.2,0) [-102.4|102.2] "" XXX
 SG_ NEW_SIGNAL_6 : 37|4@0+ (1,0) [0|255] "" XXX
 SG_ NEW_SIGNAL_7 : 38|1@0+ (1,0) [0|1] "" XXX
 SG_ NEW_SIGNAL_8 : 39|1@0+ (1,0) [0|1] "" XXX
 SG_ NEW_SIGNAL_9 : 53|14@0- (0.04,0) [-327.68|327.64] "" XXX
 SG_ NEW_SIGNAL_10 : 55|2@0+ (1,0) [0|3] "" XXX

BO_ 1623 R_0x657: 8 XXX
 SG_ NEW_SIGNAL_1 : 7|8@0- (1,0) [-128|127] "" XXX
 SG_ NEW_SIGNAL_2 : 12|10@0- (0.2,0) [-102.4|102.2] "" XXX
 SG_ NEW_SIGNAL_3 : 15|3@0+ (1,0) [0|7] "" XXX
 SG_ NEW_SIGNAL_4 : 18|11@0+ (0.1,0) [0|204.7] "" XXX
 SG_ NEW_SIGNAL_5 : 33|10@0- (0.2,0) [-102.4|102.2] "" XXX
 SG_ NEW_SIGNAL_6 : 37|4@0+ (1,0) [0|255] "" XXX
 SG_ NEW_SIGNAL_7 : 38|1@0+ (1,0) [0|1] "" XXX
 SG_ NEW_SIGNAL_8 : 39|1@0+ (1,0) [0|1] "" XXX
 SG_ NEW_SIGNAL_9 : 53|14@0- (0.04,0) [-327.68|327.64] "" XXX
 SG_ NEW_SIGNAL_10 : 55|2@0+ (1,0) [0|3] "" XXX

BO_ 1624 R_0x658: 8 XXX
 SG_ NEW_SIGNAL_1 : 7|8@0- (1,0) [-128|127] "" XXX
 SG_ NEW_SIGNAL_2 : 12|10@0- (0.2,0) [-102.4|102.2] "" XXX
 SG_ NEW_SIGNAL_3 : 15|3@0+ (1,0) [0|7] "" XXX
 SG_ NEW_SIGNAL_4 : 18|11@0+ (0.1,0) [0|204.7] "" XXX
 SG_ NEW_SIGNAL_5 : 33|10@0- (0.2,0) [-102.4|102.2] "" XXX
 SG_ NEW_SIGNAL_6 : 37|4@0+ (1,0) [0|255] "" XXX
 SG_ NEW_SIGNAL_7 : 38|1@0+ (1,0) [0|1] "" XXX
 SG_ NEW_SIGNAL_8 : 39|1@0+ (1,0) [0|1] "" XXX
 SG_ NEW_SIGNAL_9 : 53|14@0- (0.04,0) [-327.68|327.64] "" XXX
 SG_ NEW_SIGNAL_10 : 55|2@0+ (1,0) [0|3] "" XXX

BO_ 1625 R_0x659: 8 XXX
 SG_ NEW_SIGNAL_1 : 7|8@0- (1,0) [-128|127] "" XXX
 SG_ NEW_SIGNAL_2 : 12|10@0- (0.2,0) [-102.4|102.2] "" XXX
 SG_ NEW_SIGNAL_3 : 15|3@0+ (1,0) [0|7] "" XXX
 SG_ NEW_SIGNAL_4 : 18|11@0+ (0.1,0) [0|204.7] "" XXX
 SG_ NEW_SIGNAL_5 : 33|10@0- (0.2,0) [-102.4|102.2] "" XXX
 SG_ NEW_SIGNAL_6 : 37|4@0+ (1,0) [0|255] "" XXX
 SG_ NEW_SIGNAL_7 : 38|1@0+ (1,0) [0|1] "" XXX
 SG_ NEW_SIGNAL_8 : 39|1@0+ (1,0) [0|1] "" XXX
 SG_ NEW_SIGNAL_9 : 53|14@0- (0.04,0) [-327.68|327.64] "" XXX
 SG_ NEW_SIGNAL_10 : 55|2@0+ (1,0) [0|3] "" XXX

BO_ 1626 R_0x65a: 8 XXX
 SG_ NEW_SIGNAL_1 : 7|8@0- (1,0) [-128|127] "" XXX
 SG_ NEW_SIGNAL_2 : 12|10@0- (0.2,0) [-102.4|102.2] "" XXX
 SG_ NEW_SIGNAL_3 : 15|3@0+ (1,0) [0|7] "" XXX
 SG_ NEW_SIGNAL_4 : 18|11@0+ (0.1,0) [0|204.7] "" XXX
 SG_ NEW_SIGNAL_5 : 33|10@0- (0.2,0) [-102.4|102.2] "" XXX
 SG_ NEW_SIGNAL_6 : 37|4@0+ (1,0) [0|255] "" XXX
 SG_ NEW_SIGNAL_7 : 38|1@0+ (1,0) [0|1] "" XXX
 SG_ NEW_SIGNAL_8 : 39|1@0+ (1,0) [0|1] "" XXX
 SG_ NEW_SIGNAL_9 : 53|14@0- (0.04,0) [-327.68|327.64] "" XXX
 SG_ NEW_SIGNAL_10 : 55|2@0+ (1,0) [0|3] "" XXX

BO_ 1627 R_0x65b: 8 XXX
 SG_ NEW_SIGNAL_1 : 7|8@0- (1,0) [-128|127] "" XXX
 SG_ NEW_SIGNAL_2 : 12|10@0- (0.2,0) [-102.4|102.2] "" XXX
 SG_ NEW_SIGNAL_3 : 15|3@0+ (1,0) [0|7] "" XXX
 SG_ NEW_SIGNAL_4 : 18|11@0+ (0.1,0) [0|204.7] "" XXX
 SG_ NEW_SIGNAL_5 : 33|10@0- (0.2,0) [-102.4|102.2] "" XXX
 SG_ NEW_SIGNAL_6 : 37|4@0+ (1,0) [0|255] "" XXX
 SG_ NEW_SIGNAL_7 : 38|1@0+ (1,0) [0|1] "" XXX
 SG_ NEW_SIGNAL_8 : 39|1@0+ (1,0) [0|1] "" XXX
 SG_ NEW_SIGNAL_9 : 53|14@0- (0.04,0) [-327.68|327.64] "" XXX
 SG_ NEW_SIGNAL_10 : 55|2@0+ (1,0) [0|3] "" XXX

BO_ 1628 R_0x65c: 8 XXX
 SG_ NEW_SIGNAL_1 : 7|8@0- (1,0) [-128|127] "" XXX
 SG_ NEW_SIGNAL_2 : 12|10@0- (0.2,0) [-102.4|102.2] "" XXX
 SG_ NEW_SIGNAL_3 : 15|3@0+ (1,0) [0|7] "" XXX
 SG_ NEW_SIGNAL_4 : 18|11@0+ (0.1,0) [0|204.7] "" XXX
 SG_ NEW_SIGNAL_5 : 33|10@0- (0.2,0) [-102.4|102.2] "" XXX
 SG_ NEW_SIGNAL_6 : 37|4@0+ (1,0) [0|255] "" XXX
 SG_ NEW_SIGNAL_7 : 38|1@0+ (1,0) [0|1] "" XXX
 SG_ NEW_SIGNAL_8 : 39|1@0+ (1,0) [0|1] "" XXX
 SG_ NEW_SIGNAL_9 : 53|14@0- (0.04,0) [-327.68|327.64] "" XXX
 SG_ NEW_SIGNAL_10 : 55|2@0+ (1,0) [0|3] "" XXX

BO_ 1629 R_0x65d: 8 XXX
 SG_ NEW_SIGNAL_1 : 7|8@0- (1,0) [-128|127] "" XXX
 SG_ NEW_SIGNAL_2 : 12|10@0- (0.2,0) [-102.4|102.2] "" XXX
 SG_ NEW_SIGNAL_3 : 15|3@0+ (1,0) [0|7] "" XXX
 SG_ NEW_SIGNAL_4 : 18|11@0+ (0.1,0) [0|204.7] "" XXX
 SG_ NEW_SIGNAL_5 : 33|10@0- (0.2,0) [-102.4|102.2] "" XXX
 SG_ NEW_SIGNAL_6 : 37|4@0+ (1,0) [0|255] "" XXX
 SG_ NEW_SIGNAL_7 : 38|1@0+ (1,0) [0|1] "" XXX
 SG_ NEW_SIGNAL_8 : 39|1@0+ (1,0) [0|1] "" XXX
 SG_ NEW_SIGNAL_9 : 53|14@0- (0.04,0) [-327.68|327.64] "" XXX
 SG_ NEW_SIGNAL_10 : 55|2@0+ (1,0) [0|3] "" XXX

BO_ 1630 R_0x65e: 8 XXX
 SG_ NEW_SIGNAL_1 : 7|8@0- (1,0) [-128|127] "" XXX
 SG_ NEW_SIGNAL_2 : 12|10@0- (0.2,0) [-102.4|102.2] "" XXX
 SG_ NEW_SIGNAL_3 : 15|3@0+ (1,0) [0|7] "" XXX
 SG_ NEW_SIGNAL_4 : 18|11@0+ (0.1,0) [0|204.7] "" XXX
 SG_ NEW_SIGNAL_5 : 33|10@0- (0.2,0) [-102.4|102.2] "" XXX
 SG_ NEW_SIGNAL_6 : 37|4@0+ (1,0) [0|255] "" XXX
 SG_ NEW_SIGNAL_7 : 38|1@0+ (1,0) [0|1] "" XXX
 SG_ NEW_SIGNAL_8 : 39|1@0+ (1,0) [0|1] "" XXX
 SG_ NEW_SIGNAL_9 : 53|14@0- (0.04,0) [-327.68|327.64] "" XXX
 SG_ NEW_SIGNAL_10 : 55|2@0+ (1,0) [0|3] "" XXX

BO_ 1631 R_0x65f: 8 XXX
 SG_ NEW_SIGNAL_1 : 7|8@0- (1,0) [-128|127] "" XXX
 SG_ NEW_SIGNAL_2 : 12|10@0- (0.2,0) [-102.4|102.2] "" XXX
 SG_ NEW_SIGNAL_3 : 15|3@0+ (1,0) [0|7] "" XXX
 SG_ NEW_SIGNAL_4 : 18|11@0+ (0.1,0) [0|204.7] "" XXX
 SG_ NEW_SIGNAL_5 : 33|10@0- (0.2,0) [-102.4|102.2] "" XXX
 SG_ NEW_SIGNAL_6 : 37|4@0+ (1,0) [0|255] "" XXX
 SG_ NEW_SIGNAL_7 : 38|1@0+ (1,0) [0|1] "" XXX
 SG_ NEW_SIGNAL_8 : 39|1@0+ (1,0) [0|1] "" XXX
 SG_ NEW_SIGNAL_9 : 53|14@0- (0.04,0) [-327.68|327.64] "" XXX
 SG_ NEW_SIGNAL_10 : 55|2@0+ (1,0) [0|3] "" XXX

BO_ 1632 R_0x660: 8 XXX
 SG_ NEW_SIGNAL_1 : 7|8@0- (1,0) [-128|127] "" XXX
 SG_ NEW_SIGNAL_2 : 12|10@0- (0.2,0) [-102.4|102.2] "" XXX
 SG_ NEW_SIGNAL_3 : 15|3@0+ (1,0) [0|7] "" XXX
 SG_ NEW_SIGNAL_4 : 18|11@0+ (0.1,0) [0|204.7] "" XXX
 SG_ NEW_SIGNAL_5 : 33|10@0- (0.2,0) [-102.4|102.2] "" XXX
 SG_ NEW_SIGNAL_6 : 37|4@0+ (1,0) [0|255] "" XXX
 SG_ NEW_SIGNAL_7 : 38|1@0+ (1,0) [0|1] "" XXX
 SG_ NEW_SIGNAL_8 : 39|1@0+ (1,0) [0|1] "" XXX
 SG_ NEW_SIGNAL_9 : 53|14@0- (0.04,0) [-327.68|327.64] "" XXX
 SG_ NEW_SIGNAL_10 : 55|2@0+ (1,0) [0|3] "" XXX

BO_ 1633 R_0x661: 8 XXX
 SG_ NEW_SIGNAL_1 : 7|8@0- (1,0) [-128|127] "" XXX
 SG_ NEW_SIGNAL_2 : 12|10@0- (0.2,0) [-102.4|102.2] "" XXX
 SG_ NEW_SIGNAL_3 : 15|3@0+ (1,0) [0|7] "" XXX
 SG_ NEW_SIGNAL_4 : 18|11@0+ (0.1,0) [0|204.7] "" XXX
 SG_ NEW_SIGNAL_5 : 33|10@0- (0.2,0) [-102.4|102.2] "" XXX
 SG_ NEW_SIGNAL_6 : 37|4@0+ (1,0) [0|255] "" XXX
 SG_ NEW_SIGNAL_7 : 38|1@0+ (1,0) [0|1] "" XXX
 SG_ NEW_SIGNAL_8 : 39|1@0+ (1,0) [0|1] "" XXX
 SG_ NEW_SIGNAL_9 : 53|14@0- (0.04,0) [-327.68|327.64] "" XXX
 SG_ NEW_SIGNAL_10 : 55|2@0+ (1,0) [0|3] "" XXX

BO_ 1634 R_0x662: 8 XXX
 SG_ NEW_SIGNAL_1 : 7|8@0- (1,0) [-128|127] "" XXX
 SG_ NEW_SIGNAL_2 : 12|10@0- (0.2,0) [-102.4|102.2] "" XXX
 SG_ NEW_SIGNAL_3 : 15|3@0+ (1,0) [0|7] "" XXX
 SG_ NEW_SIGNAL_4 : 18|11@0+ (0.1,0) [0|204.7] "" XXX
 SG_ NEW_SIGNAL_5 : 33|10@0- (0.2,0) [-102.4|102.2] "" XXX
 SG_ NEW_SIGNAL_6 : 37|4@0+ (1,0) [0|255] "" XXX
 SG_ NEW_SIGNAL_7 : 38|1@0+ (1,0) [0|1] "" XXX
 SG_ NEW_SIGNAL_8 : 39|1@0+ (1,0) [0|1] "" XXX
 SG_ NEW_SIGNAL_9 : 53|14@0- (0.04,0) [-327.68|327.64] "" XXX
 SG_ NEW_SIGNAL_10 : 55|2@0+ (1,0) [0|3] "" XXX

BO_ 1635 R_0x663: 8 XXX
 SG_ NEW_SIGNAL_1 : 7|8@0- (1,0) [-128|127] "" XXX
 SG_ NEW_SIGNAL_2 : 12|10@0- (0.2,0) [-102.4|102.2] "" XXX
 SG_ NEW_SIGNAL_3 : 15|3@0+ (1,0) [0|7] "" XXX
 SG_ NEW_SIGNAL_4 : 18|11@0+ (0.1,0) [0|204.7] "" XXX
 SG_ NEW_SIGNAL_5 : 33|10@0- (0.2,0) [-102.4|102.2] "" XXX
 SG_ NEW_SIGNAL_6 : 37|4@0+ (1,0) [0|255] "" XXX
 SG_ NEW_SIGNAL_7 : 38|1@0+ (1,0) [0|1] "" XXX
 SG_ NEW_SIGNAL_8 : 39|1@0+ (1,0) [0|1] "" XXX
 SG_ NEW_SIGNAL_9 : 53|14@0- (0.04,0) [-327.68|327.64] "" XXX
 SG_ NEW_SIGNAL_10 : 55|2@0+ (1,0) [0|3] "" XXX

BO_ 1636 R_0x664: 8 XXX
 SG_ NEW_SIGNAL_1 : 7|8@0- (1,0) [-128|127] "" XXX
 SG_ NEW_SIGNAL_2 : 12|10@0- (0.2,0) [-102.4|102.2] "" XXX
 SG_ NEW_SIGNAL_3 : 15|3@0+ (1,0) [0|7] "" XXX
 SG_ NEW_SIGNAL_4 : 18|11@0+ (0.1,0) [0|204.7] "" XXX
 SG_ NEW_SIGNAL_5 : 33|10@0- (0.2,0) [-102.4|102.2] "" XXX
 SG_ NEW_SIGNAL_6 : 37|4@0+ (1,0) [0|255] "" XXX
 SG_ NEW_SIGNAL_7 : 38|1@0+ (1,0) [0|1] "" XXX
 SG_ NEW_SIGNAL_8 : 39|1@0+ (1,0) [0|1] "" XXX
 SG_ NEW_SIGNAL_9 : 53|14@0- (0.04,0) [-327.68|327.64] "" XXX
 SG_ NEW_SIGNAL_10 : 55|2@0+ (1,0) [0|3] "" XXX

BO_ 1637 R_0x665: 8 XXX
 SG_ NEW_SIGNAL_1 : 7|8@0- (1,0) [-128|127] "" XXX
 SG_ NEW_SIGNAL_2 : 12|10@0- (0.2,0) [-102.4|102.2] "" XXX
 SG_ NEW_SIGNAL_3 : 15|3@0+ (1,0) [0|7] "" XXX
 SG_ NEW_SIGNAL_4 : 18|11@0+ (0.1,0) [0|204.7] "" XXX
 SG_ NEW_SIGNAL_5 : 33|10@0- (0.2,0) [-102.4|102.2] "" XXX
 SG_ NEW_SIGNAL_6 : 37|4@0+ (1,0) [0|255] "" XXX
 SG_ NEW_SIGNAL_7 : 38|1@0+ (1,0) [0|1] "" XXX
 SG_ NEW_SIGNAL_8 : 39|1@0+ (1,0) [0|1] "" XXX
 SG_ NEW_SIGNAL_9 : 53|14@0- (0.04,0) [-327.68|327.64] "" XXX
 SG_ NEW_SIGNAL_10 : 55|2@0+ (1,0) [0|3] "" XXX

BO_ 1638 R_0x666: 8 XXX
 SG_ NEW_SIGNAL_1 : 7|8@0- (1,0) [-128|127] "" XXX
 SG_ NEW_SIGNAL_2 : 12|10@0- (0.2,0) [-102.4|102.2] "" XXX
 SG_ NEW_SIGNAL_3 : 15|3@0+ (1,0) [0|7] "" XXX
 SG_ NEW_SIGNAL_4 : 18|11@0+ (0.1,0) [0|204.7] "" XXX
 SG_ NEW_SIGNAL_5 : 33|10@0- (0.2,0) [-102.4|102.2] "" XXX
 SG_ NEW_SIGNAL_6 : 37|4@0+ (1,0) [0|255] "" XXX
 SG_ NEW_SIGNAL_7 : 38|1@0+ (1,0) [0|1] "" XXX
 SG_ NEW_SIGNAL_8 : 39|1@0+ (1,0) [0|1] "" XXX
 SG_ NEW_SIGNAL_9 : 53|14@0- (0.04,0) [-327.68|327.64] "" XXX
 SG_ NEW_SIGNAL_10 : 55|2@0+ (1,0) [0|3] "" XXX

BO_ 1639 R_0x667: 8 XXX
 SG_ NEW_SIGNAL_1 : 7|8@0- (1,0) [-128|127] "" XXX
 SG_ NEW_SIGNAL_2 : 12|10@0- (0.2,0) [-102.4|102.2] "" XXX
 SG_ NEW_SIGNAL_3 : 15|3@0+ (1,0) [0|7] "" XXX
 SG_ NEW_SIGNAL_4 : 18|11@0+ (0.1,0) [0|204.7] "" XXX
 SG_ NEW_SIGNAL_5 : 33|10@0- (0.2,0) [-102.4|102.2] "" XXX
 SG_ NEW_SIGNAL_6 : 37|4@0+ (1,0) [0|255] "" XXX
 SG_ NEW_SIGNAL_7 : 38|1@0+ (1,0) [0|1] "" XXX
 SG_ NEW_SIGNAL_8 : 39|1@0+ (1,0) [0|1] "" XXX
 SG_ NEW_SIGNAL_9 : 53|14@0- (0.04,0) [-327.68|327.64] "" XXX
 SG_ NEW_SIGNAL_10 : 55|2@0+ (1,0) [0|3] "" XXX

BO_ 1640 R_0x668: 8 XXX
 SG_ NEW_SIGNAL_1 : 7|8@0- (1,0) [-128|127] "" XXX
 SG_ NEW_SIGNAL_2 : 12|10@0- (0.2,0) [-102.4|102.2] "" XXX
 SG_ NEW_SIGNAL_3 : 15|3@0+ (1,0) [0|7] "" XXX
 SG_ NEW_SIGNAL_4 : 18|11@0+ (0.1,0) [0|204.7] "" XXX
 SG_ NEW_SIGNAL_5 : 33|10@0- (0.2,0) [-102.4|102.2] "" XXX
 SG_ NEW_SIGNAL_6 : 37|4@0+ (1,0) [0|255] "" XXX
 SG_ NEW_SIGNAL_7 : 38|1@0+ (1,0) [0|1] "" XXX
 SG_ NEW_SIGNAL_8 : 39|1@0+ (1,0) [0|1] "" XXX
 SG_ NEW_SIGNAL_9 : 53|14@0- (0.04,0) [-327.68|327.64] "" XXX
 SG_ NEW_SIGNAL_10 : 55|2@0+ (1,0) [0|3] "" XXX

BO_ 1641 R_0x669: 8 XXX
 SG_ NEW_SIGNAL_1 : 7|8@0- (1,0) [-128|127] "" XXX
 SG_ NEW_SIGNAL_2 : 12|10@0- (0.2,0) [-102.4|102.2] "" XXX
 SG_ NEW_SIGNAL_3 : 15|3@0+ (1,0) [0|7] "" XXX
 SG_ NEW_SIGNAL_4 : 18|11@0+ (0.1,0) [0|204.7] "" XXX
 SG_ NEW_SIGNAL_5 : 33|10@0- (0.2,0) [-102.4|102.2] "" XXX
 SG_ NEW_SIGNAL_6 : 37|4@0+ (1,0) [0|255] "" XXX
 SG_ NEW_SIGNAL_7 : 38|1@0+ (1,0) [0|1] "" XXX
 SG_ NEW_SIGNAL_8 : 39|1@0+ (1,0) [0|1] "" XXX
 SG_ NEW_SIGNAL_9 : 53|14@0- (0.04,0) [-327.68|327.64] "" XXX
 SG_ NEW_SIGNAL_10 : 55|2@0+ (1,0) [0|3] "" XXX

BO_ 1642 R_0x66a: 8 XXX
 SG_ NEW_SIGNAL_1 : 7|8@0- (1,0) [-128|127] "" XXX
 SG_ NEW_SIGNAL_2 : 12|10@0- (0.2,0) [-102.4|102.2] "" XXX
 SG_ NEW_SIGNAL_3 : 15|3@0+ (1,0) [0|7] "" XXX
 SG_ NEW_SIGNAL_4 : 18|11@0+ (0.1,0) [0|204.7] "" XXX
 SG_ NEW_SIGNAL_5 : 33|10@0- (0.2,0) [-102.4|102.2] "" XXX
 SG_ NEW_SIGNAL_6 : 37|4@0+ (1,0) [0|255] "" XXX
 SG_ NEW_SIGNAL_7 : 38|1@0+ (1,0) [0|1] "" XXX
 SG_ NEW_SIGNAL_8 : 39|1@0+ (1,0) [0|1] "" XXX
 SG_ NEW_SIGNAL_9 : 53|14@0- (0.04,0) [-327.68|327.64] "" XXX
 SG_ NEW_SIGNAL_10 : 55|2@0+ (1,0) [0|3] "" XXX

BO_ 1643 R_0x66b: 8 XXX
 SG_ NEW_SIGNAL_1 : 7|8@0- (1,0) [-128|127] "" XXX
 SG_ NEW_SIGNAL_2 : 12|10@0- (0.2,0) [-102.4|102.2] "" XXX
 SG_ NEW_SIGNAL_3 : 15|3@0+ (1,0) [0|7] "" XXX
 SG_ NEW_SIGNAL_4 : 18|11@0+ (0.1,0) [0|204.7] "" XXX
 SG_ NEW_SIGNAL_5 : 33|10@0- (0.2,0) [-102.4|102.2] "" XXX
 SG_ NEW_SIGNAL_6 : 37|4@0+ (1,0) [0|255] "" XXX
 SG_ NEW_SIGNAL_7 : 38|1@0+ (1,0) [0|1] "" XXX
 SG_ NEW_SIGNAL_8 : 39|1@0+ (1,0) [0|1] "" XXX
 SG_ NEW_SIGNAL_9 : 53|14@0- (0.04,0) [-327.68|327.64] "" XXX
 SG_ NEW_SIGNAL_10 : 55|2@0+ (1,0) [0|3] "" XXX

BO_ 1644 R_0x66c: 8 XXX
 SG_ NEW_SIGNAL_1 : 7|8@0- (1,0) [-128|127] "" XXX
 SG_ NEW_SIGNAL_2 : 12|10@0- (0.2,0) [-102.4|102.2] "" XXX
 SG_ NEW_SIGNAL_3 : 15|3@0+ (1,0) [0|7] "" XXX
 SG_ NEW_SIGNAL_4 : 18|11@0+ (0.1,0) [0|204.7] "" XXX
 SG_ NEW_SIGNAL_5 : 33|10@0- (0.2,0) [-102.4|102.2] "" XXX
 SG_ NEW_SIGNAL_6 : 37|4@0+ (1,0) [0|255] "" XXX
 SG_ NEW_SIGNAL_7 : 38|1@0+ (1,0) [0|1] "" XXX
 SG_ NEW_SIGNAL_8 : 39|1@0+ (1,0) [0|1] "" XXX
 SG_ NEW_SIGNAL_9 : 53|14@0- (0.04,0) [-327.68|327.64] "" XXX
 SG_ NEW_SIGNAL_10 : 55|2@0+ (1,0) [0|3] "" XXX

BO_ 1645 R_0x66d: 8 XXX
 SG_ NEW_SIGNAL_1 : 7|8@0- (1,0) [-128|127] "" XXX
 SG_ NEW_SIGNAL_2 : 12|10@0- (0.2,0) [-102.4|102.2] "" XXX
 SG_ NEW_SIGNAL_3 : 15|3@0+ (1,0) [0|7] "" XXX
 SG_ NEW_SIGNAL_4 : 18|11@0+ (0.1,0) [0|204.7] "" XXX
 SG_ NEW_SIGNAL_5 : 33|10@0- (0.2,0) [-102.4|102.2] "" XXX
 SG_ NEW_SIGNAL_6 : 37|4@0+ (1,0) [0|255] "" XXX
 SG_ NEW_SIGNAL_7 : 38|1@0+ (1,0) [0|1] "" XXX
 SG_ NEW_SIGNAL_8 : 39|1@0+ (1,0) [0|1] "" XXX
 SG_ NEW_SIGNAL_9 : 53|14@0- (0.04,0) [-327.68|327.64] "" XXX
 SG_ NEW_SIGNAL_10 : 55|2@0+ (1,0) [0|3] "" XXX

BO_ 1664 R_0x680: 8 XXX

BO_ 1665 R_0x681: 8 XXX

BO_ 1666 R_0x682: 8 XXX

BO_ 1667 R_0x683: 8 XXX

BO_ 1668 R_0x684: 8 XXX

BO_ 1669 R_0x685: 8 XXX

BO_ 1670 R_0x686: 8 XXX

BO_ 1671 R_0x687: 8 XXX

BO_ 1672 R_0x688: 8 XXX

BO_ 1673 R_0x689: 8 XXX

BO_ 1674 R_0x68a: 8 XXX

BO_ 1675 R_0x68b: 8 XXX

BO_ 1676 R_0x68c: 8 XXX

BO_ 1677 R_0x68d: 8 XXX

BO_ 1678 R_0x68e: 8 XXX

BO_ 1679 R_0x68f: 8 XXX

BO_ 1680 R_0x690: 8 XXX

BO_ 1681 R_0x691: 8 XXX

BO_ 1682 R_0x692: 8 XXX

BO_ 1683 R_0x693: 8 XXX

BO_ 1684 R_0x694: 8 XXX

BO_ 1685 R_0x695: 8 XXX

BO_ 1686 R_0x696: 8 XXX

BO_ 1687 R_0x697: 8 XXX

BO_ 1688 R_0x698: 8 XXX

BO_ 1689 R_0x699: 8 XXX

BO_ 1690 R_0x69a: 8 XXX

BO_ 1691 R_0x69b: 8 XXX

BO_ 1692 R_0x69c: 8 XXX

BO_ 1693 R_0x69d: 8 XXX

BO_ 1694 R_0x69e: 8 XXX

BO_ 1695 R_0x69f: 8 XXX

BO_ 1696 R_0x5ED: 8 XXX
BO_ 1697 R_0x5EE: 8 XXX
BO_ 1698 R_0x5EF: 8 XXX

BO_ 1696 R_0x6A0: 8 XXX
BO_ 1697 R_0x6A1: 8 XXX
BO_ 1698 R_0x6A2: 8 XXX
BO_ 1699 R_0x6A3: 8 XXX
BO_ 1700 R_0x6A4: 8 XXX
